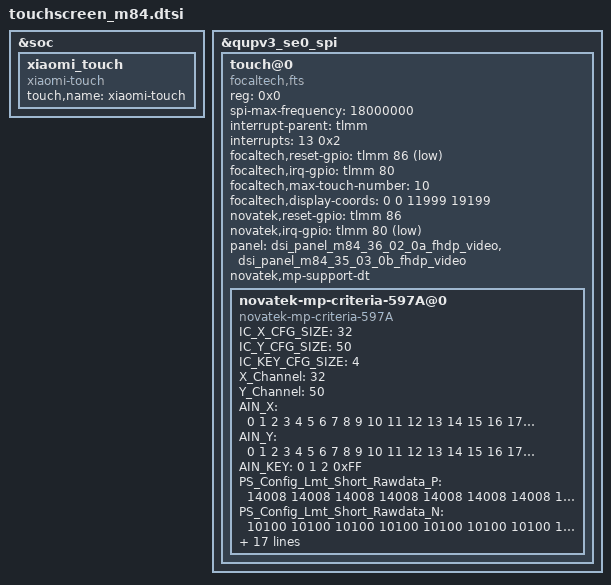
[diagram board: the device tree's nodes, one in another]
/*
 * TouchScreen Device Tree For Xiaomi m84
 */
&soc {
	xiaomi_touch {
		status = "okay";
		compatible = "xiaomi-touch";
		touch,name = "xiaomi-touch";
	};
};

&qupv3_se0_spi {
	status = "okay";
		touch@0 {
			compatible = "focaltech,fts","novatek,NVT-ts-spi";
			reg = <0x0>;
			status = "ok";
			spi-max-frequency = <18000000>;
			interrupt-parent = <&tlmm>;
			interrupts = <13 0x2>;
/***********************************focaltech dtsi **********************************/
			focaltech,reset-gpio = <&tlmm 86 0x01>;
			focaltech,irq-gpio = <&tlmm 80 0x02>;
			focaltech,max-touch-number = <10>;
			focaltech,display-coords =  <0 0 11999 19199>;

			/*pinctrl-names = "pmx_ts_active","pmx_ts_suspend","pmx_ts_release";
			pinctrl-0 = <&ts_int_active &ts_reset_active>;
			pinctrl-1 = <&ts_int_suspend &ts_reset_suspend>;
			pinctrl-2 = <&ts_release>; */
/***********************************novatek dtsi ************************************/ 
			novatek,reset-gpio = <&tlmm 86 0x00>;
			novatek,irq-gpio = <&tlmm 80 0x2001>;
			panel = <&dsi_panel_m84_36_02_0a_fhdp_video &dsi_panel_m84_35_03_0b_fhdp_video>;

			//novatek,pen-support;
			//novatek,stylus-resol-double;

			//novatek,spi-rd-fast-addr = <0x03F310>;

			/* MP */
			novatek,mp-support-dt;

		novatek-mp-criteria-597A@0 {
			#address-cells = <1>;
			#size-cells = <0>;
			compatible = "novatek-mp-criteria-597A";

			/* MP Config */
			IC_X_CFG_SIZE = <32>;
			IC_Y_CFG_SIZE = <50>;
			IC_KEY_CFG_SIZE = <4>;
			X_Channel = <32>;
			Y_Channel = <50>;
			AIN_X = <0 1 2 3 4 5 6 7 8 9 10 11 12 13 14 15 16 17 18 19 20 21 22 23 24 25 26 27 28 29 30 31>;
			AIN_Y = <0 1 2 3 4 5 6 7 8 9 10 11 12 13 14 15 16 17 18 19 20 21 22 23 24 25 26 27 28 29 30 31 32 33 34 35 36 37 38 39 40 41 42 43 44 45 46 47 48 49>;
			AIN_KEY = <0 1 2 0xFF>;

			/* MP Criteria */
			PS_Config_Lmt_Short_Rawdata_P = <
				14008 14008 14008 14008 14008 14008 14008 14008 14008 14008 14008 14008 14008 14008 14008 14008 14008 14008 14008 14008 14008 14008 14008 14008 14008 14008 14008 14008 14008 14008 14008 14008
				14008 14008 14008 14008 14008 14008 14008 14008 14008 14008 14008 14008 14008 14008 14008 14008 14008 14008 14008 14008 14008 14008 14008 14008 14008 14008 14008 14008 14008 14008 14008 14008
				14008 14008 14008 14008 14008 14008 14008 14008 14008 14008 14008 14008 14008 14008 14008 14008 14008 14008 14008 14008 14008 14008 14008 14008 14008 14008 14008 14008 14008 14008 14008 14008
				14008 14008 14008 14008 14008 14008 14008 14008 14008 14008 14008 14008 14008 14008 14008 14008 14008 14008 14008 14008 14008 14008 14008 14008 14008 14008 14008 14008 14008 14008 14008 14008
				14008 14008 14008 14008 14008 14008 14008 14008 14008 14008 14008 14008 14008 14008 14008 14008 14008 14008 14008 14008 14008 14008 14008 14008 14008 14008 14008 14008 14008 14008 14008 14008
				14008 14008 14008 14008 14008 14008 14008 14008 14008 14008 14008 14008 14008 14008 14008 14008 14008 14008 14008 14008 14008 14008 14008 14008 14008 14008 14008 14008 14008 14008 14008 14008
				14008 14008 14008 14008 14008 14008 14008 14008 14008 14008 14008 14008 14008 14008 14008 14008 14008 14008 14008 14008 14008 14008 14008 14008 14008 14008 14008 14008 14008 14008 14008 14008
				14008 14008 14008 14008 14008 14008 14008 14008 14008 14008 14008 14008 14008 14008 14008 14008 14008 14008 14008 14008 14008 14008 14008 14008 14008 14008 14008 14008 14008 14008 14008 14008
				14008 14008 14008 14008 14008 14008 14008 14008 14008 14008 14008 14008 14008 14008 14008 14008 14008 14008 14008 14008 14008 14008 14008 14008 14008 14008 14008 14008 14008 14008 14008 14008
				14008 14008 14008 14008 14008 14008 14008 14008 14008 14008 14008 14008 14008 14008 14008 14008 14008 14008 14008 14008 14008 14008 14008 14008 14008 14008 14008 14008 14008 14008 14008 14008
				14008 14008 14008 14008 14008 14008 14008 14008 14008 14008 14008 14008 14008 14008 14008 14008 14008 14008 14008 14008 14008 14008 14008 14008 14008 14008 14008 14008 14008 14008 14008 14008
				14008 14008 14008 14008 14008 14008 14008 14008 14008 14008 14008 14008 14008 14008 14008 14008 14008 14008 14008 14008 14008 14008 14008 14008 14008 14008 14008 14008 14008 14008 14008 14008
				14008 14008 14008 14008 14008 14008 14008 14008 14008 14008 14008 14008 14008 14008 14008 14008 14008 14008 14008 14008 14008 14008 14008 14008 14008 14008 14008 14008 14008 14008 14008 14008
				14008 14008 14008 14008 14008 14008 14008 14008 14008 14008 14008 14008 14008 14008 14008 14008 14008 14008 14008 14008 14008 14008 14008 14008 14008 14008 14008 14008 14008 14008 14008 14008
				14008 14008 14008 14008 14008 14008 14008 14008 14008 14008 14008 14008 14008 14008 14008 14008 14008 14008 14008 14008 14008 14008 14008 14008 14008 14008 14008 14008 14008 14008 14008 14008
				14008 14008 14008 14008 14008 14008 14008 14008 14008 14008 14008 14008 14008 14008 14008 14008 14008 14008 14008 14008 14008 14008 14008 14008 14008 14008 14008 14008 14008 14008 14008 14008
				14008 14008 14008 14008 14008 14008 14008 14008 14008 14008 14008 14008 14008 14008 14008 14008 14008 14008 14008 14008 14008 14008 14008 14008 14008 14008 14008 14008 14008 14008 14008 14008
				14008 14008 14008 14008 14008 14008 14008 14008 14008 14008 14008 14008 14008 14008 14008 14008 14008 14008 14008 14008 14008 14008 14008 14008 14008 14008 14008 14008 14008 14008 14008 14008
				14008 14008 14008 14008 14008 14008 14008 14008 14008 14008 14008 14008 14008 14008 14008 14008 14008 14008 14008 14008 14008 14008 14008 14008 14008 14008 14008 14008 14008 14008 14008 14008
				14008 14008 14008 14008 14008 14008 14008 14008 14008 14008 14008 14008 14008 14008 14008 14008 14008 14008 14008 14008 14008 14008 14008 14008 14008 14008 14008 14008 14008 14008 14008 14008
				14008 14008 14008 14008 14008 14008 14008 14008 14008 14008 14008 14008 14008 14008 14008 14008 14008 14008 14008 14008 14008 14008 14008 14008 14008 14008 14008 14008 14008 14008 14008 14008
				14008 14008 14008 14008 14008 14008 14008 14008 14008 14008 14008 14008 14008 14008 14008 14008 14008 14008 14008 14008 14008 14008 14008 14008 14008 14008 14008 14008 14008 14008 14008 14008
				14008 14008 14008 14008 14008 14008 14008 14008 14008 14008 14008 14008 14008 14008 14008 14008 14008 14008 14008 14008 14008 14008 14008 14008 14008 14008 14008 14008 14008 14008 14008 14008
				14008 14008 14008 14008 14008 14008 14008 14008 14008 14008 14008 14008 14008 14008 14008 14008 14008 14008 14008 14008 14008 14008 14008 14008 14008 14008 14008 14008 14008 14008 14008 14008
				14008 14008 14008 14008 14008 14008 14008 14008 14008 14008 14008 14008 14008 14008 14008 14008 14008 14008 14008 14008 14008 14008 14008 14008 14008 14008 14008 14008 14008 14008 14008 14008
				14008 14008 14008 14008 14008 14008 14008 14008 14008 14008 14008 14008 14008 14008 14008 14008 14008 14008 14008 14008 14008 14008 14008 14008 14008 14008 14008 14008 14008 14008 14008 14008
				14008 14008 14008 14008 14008 14008 14008 14008 14008 14008 14008 14008 14008 14008 14008 14008 14008 14008 14008 14008 14008 14008 14008 14008 14008 14008 14008 14008 14008 14008 14008 14008
				14008 14008 14008 14008 14008 14008 14008 14008 14008 14008 14008 14008 14008 14008 14008 14008 14008 14008 14008 14008 14008 14008 14008 14008 14008 14008 14008 14008 14008 14008 14008 14008
				14008 14008 14008 14008 14008 14008 14008 14008 14008 14008 14008 14008 14008 14008 14008 14008 14008 14008 14008 14008 14008 14008 14008 14008 14008 14008 14008 14008 14008 14008 14008 14008
				14008 14008 14008 14008 14008 14008 14008 14008 14008 14008 14008 14008 14008 14008 14008 14008 14008 14008 14008 14008 14008 14008 14008 14008 14008 14008 14008 14008 14008 14008 14008 14008
				14008 14008 14008 14008 14008 14008 14008 14008 14008 14008 14008 14008 14008 14008 14008 14008 14008 14008 14008 14008 14008 14008 14008 14008 14008 14008 14008 14008 14008 14008 14008 14008
				14008 14008 14008 14008 14008 14008 14008 14008 14008 14008 14008 14008 14008 14008 14008 14008 14008 14008 14008 14008 14008 14008 14008 14008 14008 14008 14008 14008 14008 14008 14008 14008
				14008 14008 14008 14008 14008 14008 14008 14008 14008 14008 14008 14008 14008 14008 14008 14008 14008 14008 14008 14008 14008 14008 14008 14008 14008 14008 14008 14008 14008 14008 14008 14008
				14008 14008 14008 14008 14008 14008 14008 14008 14008 14008 14008 14008 14008 14008 14008 14008 14008 14008 14008 14008 14008 14008 14008 14008 14008 14008 14008 14008 14008 14008 14008 14008
				14008 14008 14008 14008 14008 14008 14008 14008 14008 14008 14008 14008 14008 14008 14008 14008 14008 14008 14008 14008 14008 14008 14008 14008 14008 14008 14008 14008 14008 14008 14008 14008
				14008 14008 14008 14008 14008 14008 14008 14008 14008 14008 14008 14008 14008 14008 14008 14008 14008 14008 14008 14008 14008 14008 14008 14008 14008 14008 14008 14008 14008 14008 14008 14008
				14008 14008 14008 14008 14008 14008 14008 14008 14008 14008 14008 14008 14008 14008 14008 14008 14008 14008 14008 14008 14008 14008 14008 14008 14008 14008 14008 14008 14008 14008 14008 14008
				14008 14008 14008 14008 14008 14008 14008 14008 14008 14008 14008 14008 14008 14008 14008 14008 14008 14008 14008 14008 14008 14008 14008 14008 14008 14008 14008 14008 14008 14008 14008 14008
				14008 14008 14008 14008 14008 14008 14008 14008 14008 14008 14008 14008 14008 14008 14008 14008 14008 14008 14008 14008 14008 14008 14008 14008 14008 14008 14008 14008 14008 14008 14008 14008
				14008 14008 14008 14008 14008 14008 14008 14008 14008 14008 14008 14008 14008 14008 14008 14008 14008 14008 14008 14008 14008 14008 14008 14008 14008 14008 14008 14008 14008 14008 14008 14008
				14008 14008 14008 14008 14008 14008 14008 14008 14008 14008 14008 14008 14008 14008 14008 14008 14008 14008 14008 14008 14008 14008 14008 14008 14008 14008 14008 14008 14008 14008 14008 14008
				14008 14008 14008 14008 14008 14008 14008 14008 14008 14008 14008 14008 14008 14008 14008 14008 14008 14008 14008 14008 14008 14008 14008 14008 14008 14008 14008 14008 14008 14008 14008 14008
				14008 14008 14008 14008 14008 14008 14008 14008 14008 14008 14008 14008 14008 14008 14008 14008 14008 14008 14008 14008 14008 14008 14008 14008 14008 14008 14008 14008 14008 14008 14008 14008
				14008 14008 14008 14008 14008 14008 14008 14008 14008 14008 14008 14008 14008 14008 14008 14008 14008 14008 14008 14008 14008 14008 14008 14008 14008 14008 14008 14008 14008 14008 14008 14008
				14008 14008 14008 14008 14008 14008 14008 14008 14008 14008 14008 14008 14008 14008 14008 14008 14008 14008 14008 14008 14008 14008 14008 14008 14008 14008 14008 14008 14008 14008 14008 14008
				14008 14008 14008 14008 14008 14008 14008 14008 14008 14008 14008 14008 14008 14008 14008 14008 14008 14008 14008 14008 14008 14008 14008 14008 14008 14008 14008 14008 14008 14008 14008 14008
				14008 14008 14008 14008 14008 14008 14008 14008 14008 14008 14008 14008 14008 14008 14008 14008 14008 14008 14008 14008 14008 14008 14008 14008 14008 14008 14008 14008 14008 14008 14008 14008
				14008 14008 14008 14008 14008 14008 14008 14008 14008 14008 14008 14008 14008 14008 14008 14008 14008 14008 14008 14008 14008 14008 14008 14008 14008 14008 14008 14008 14008 14008 14008 14008
				14008 14008 14008 14008 14008 14008 14008 14008 14008 14008 14008 14008 14008 14008 14008 14008 14008 14008 14008 14008 14008 14008 14008 14008 14008 14008 14008 14008 14008 14008 14008 14008
				14008 14008 14008 14008 14008 14008 14008 14008 14008 14008 14008 14008 14008 14008 14008 14008 14008 14008 14008 14008 14008 14008 14008 14008 14008 14008 14008 14008 14008 14008 14008 14008
				14008 14008 14008>;

			PS_Config_Lmt_Short_Rawdata_N = <
				10100 10100 10100 10100 10100 10100 10100 10100 10100 10100 10100 10100 10100 10100 10100 10100 10100 10100 10100 10100 10100 10100 10100 10100 10100 10100 10100 10100 10100 10100 10100 10100
				10100 10100 10100 10100 10100 10100 10100 10100 10100 10100 10100 10100 10100 10100 10100 10100 10100 10100 10100 10100 10100 10100 10100 10100 10100 10100 10100 10100 10100 10100 10100 10100
				10100 10100 10100 10100 10100 10100 10100 10100 10100 10100 10100 10100 10100 10100 10100 10100 10100 10100 10100 10100 10100 10100 10100 10100 10100 10100 10100 10100 10100 10100 10100 10100
				10100 10100 10100 10100 10100 10100 10100 10100 10100 10100 10100 10100 10100 10100 10100 10100 10100 10100 10100 10100 10100 10100 10100 10100 10100 10100 10100 10100 10100 10100 10100 10100
				10100 10100 10100 10100 10100 10100 10100 10100 10100 10100 10100 10100 10100 10100 10100 10100 10100 10100 10100 10100 10100 10100 10100 10100 10100 10100 10100 10100 10100 10100 10100 10100
				10100 10100 10100 10100 10100 10100 10100 10100 10100 10100 10100 10100 10100 10100 10100 10100 10100 10100 10100 10100 10100 10100 10100 10100 10100 10100 10100 10100 10100 10100 10100 10100
				10100 10100 10100 10100 10100 10100 10100 10100 10100 10100 10100 10100 10100 10100 10100 10100 10100 10100 10100 10100 10100 10100 10100 10100 10100 10100 10100 10100 10100 10100 10100 10100
				10100 10100 10100 10100 10100 10100 10100 10100 10100 10100 10100 10100 10100 10100 10100 10100 10100 10100 10100 10100 10100 10100 10100 10100 10100 10100 10100 10100 10100 10100 10100 10100
				10100 10100 10100 10100 10100 10100 10100 10100 10100 10100 10100 10100 10100 10100 10100 10100 10100 10100 10100 10100 10100 10100 10100 10100 10100 10100 10100 10100 10100 10100 10100 10100
				10100 10100 10100 10100 10100 10100 10100 10100 10100 10100 10100 10100 10100 10100 10100 10100 10100 10100 10100 10100 10100 10100 10100 10100 10100 10100 10100 10100 10100 10100 10100 10100
				10100 10100 10100 10100 10100 10100 10100 10100 10100 10100 10100 10100 10100 10100 10100 10100 10100 10100 10100 10100 10100 10100 10100 10100 10100 10100 10100 10100 10100 10100 10100 10100
				10100 10100 10100 10100 10100 10100 10100 10100 10100 10100 10100 10100 10100 10100 10100 10100 10100 10100 10100 10100 10100 10100 10100 10100 10100 10100 10100 10100 10100 10100 10100 10100
				10100 10100 10100 10100 10100 10100 10100 10100 10100 10100 10100 10100 10100 10100 10100 10100 10100 10100 10100 10100 10100 10100 10100 10100 10100 10100 10100 10100 10100 10100 10100 10100
				10100 10100 10100 10100 10100 10100 10100 10100 10100 10100 10100 10100 10100 10100 10100 10100 10100 10100 10100 10100 10100 10100 10100 10100 10100 10100 10100 10100 10100 10100 10100 10100
				10100 10100 10100 10100 10100 10100 10100 10100 10100 10100 10100 10100 10100 10100 10100 10100 10100 10100 10100 10100 10100 10100 10100 10100 10100 10100 10100 10100 10100 10100 10100 10100
				10100 10100 10100 10100 10100 10100 10100 10100 10100 10100 10100 10100 10100 10100 10100 10100 10100 10100 10100 10100 10100 10100 10100 10100 10100 10100 10100 10100 10100 10100 10100 10100
				10100 10100 10100 10100 10100 10100 10100 10100 10100 10100 10100 10100 10100 10100 10100 10100 10100 10100 10100 10100 10100 10100 10100 10100 10100 10100 10100 10100 10100 10100 10100 10100
				10100 10100 10100 10100 10100 10100 10100 10100 10100 10100 10100 10100 10100 10100 10100 10100 10100 10100 10100 10100 10100 10100 10100 10100 10100 10100 10100 10100 10100 10100 10100 10100
				10100 10100 10100 10100 10100 10100 10100 10100 10100 10100 10100 10100 10100 10100 10100 10100 10100 10100 10100 10100 10100 10100 10100 10100 10100 10100 10100 10100 10100 10100 10100 10100
				10100 10100 10100 10100 10100 10100 10100 10100 10100 10100 10100 10100 10100 10100 10100 10100 10100 10100 10100 10100 10100 10100 10100 10100 10100 10100 10100 10100 10100 10100 10100 10100
				10100 10100 10100 10100 10100 10100 10100 10100 10100 10100 10100 10100 10100 10100 10100 10100 10100 10100 10100 10100 10100 10100 10100 10100 10100 10100 10100 10100 10100 10100 10100 10100
				10100 10100 10100 10100 10100 10100 10100 10100 10100 10100 10100 10100 10100 10100 10100 10100 10100 10100 10100 10100 10100 10100 10100 10100 10100 10100 10100 10100 10100 10100 10100 10100
				10100 10100 10100 10100 10100 10100 10100 10100 10100 10100 10100 10100 10100 10100 10100 10100 10100 10100 10100 10100 10100 10100 10100 10100 10100 10100 10100 10100 10100 10100 10100 10100
				10100 10100 10100 10100 10100 10100 10100 10100 10100 10100 10100 10100 10100 10100 10100 10100 10100 10100 10100 10100 10100 10100 10100 10100 10100 10100 10100 10100 10100 10100 10100 10100
				10100 10100 10100 10100 10100 10100 10100 10100 10100 10100 10100 10100 10100 10100 10100 10100 10100 10100 10100 10100 10100 10100 10100 10100 10100 10100 10100 10100 10100 10100 10100 10100
				10100 10100 10100 10100 10100 10100 10100 10100 10100 10100 10100 10100 10100 10100 10100 10100 10100 10100 10100 10100 10100 10100 10100 10100 10100 10100 10100 10100 10100 10100 10100 10100
				10100 10100 10100 10100 10100 10100 10100 10100 10100 10100 10100 10100 10100 10100 10100 10100 10100 10100 10100 10100 10100 10100 10100 10100 10100 10100 10100 10100 10100 10100 10100 10100
				10100 10100 10100 10100 10100 10100 10100 10100 10100 10100 10100 10100 10100 10100 10100 10100 10100 10100 10100 10100 10100 10100 10100 10100 10100 10100 10100 10100 10100 10100 10100 10100
				10100 10100 10100 10100 10100 10100 10100 10100 10100 10100 10100 10100 10100 10100 10100 10100 10100 10100 10100 10100 10100 10100 10100 10100 10100 10100 10100 10100 10100 10100 10100 10100
				10100 10100 10100 10100 10100 10100 10100 10100 10100 10100 10100 10100 10100 10100 10100 10100 10100 10100 10100 10100 10100 10100 10100 10100 10100 10100 10100 10100 10100 10100 10100 10100
				10100 10100 10100 10100 10100 10100 10100 10100 10100 10100 10100 10100 10100 10100 10100 10100 10100 10100 10100 10100 10100 10100 10100 10100 10100 10100 10100 10100 10100 10100 10100 10100
				10100 10100 10100 10100 10100 10100 10100 10100 10100 10100 10100 10100 10100 10100 10100 10100 10100 10100 10100 10100 10100 10100 10100 10100 10100 10100 10100 10100 10100 10100 10100 10100
				10100 10100 10100 10100 10100 10100 10100 10100 10100 10100 10100 10100 10100 10100 10100 10100 10100 10100 10100 10100 10100 10100 10100 10100 10100 10100 10100 10100 10100 10100 10100 10100
				10100 10100 10100 10100 10100 10100 10100 10100 10100 10100 10100 10100 10100 10100 10100 10100 10100 10100 10100 10100 10100 10100 10100 10100 10100 10100 10100 10100 10100 10100 10100 10100
				10100 10100 10100 10100 10100 10100 10100 10100 10100 10100 10100 10100 10100 10100 10100 10100 10100 10100 10100 10100 10100 10100 10100 10100 10100 10100 10100 10100 10100 10100 10100 10100
				10100 10100 10100 10100 10100 10100 10100 10100 10100 10100 10100 10100 10100 10100 10100 10100 10100 10100 10100 10100 10100 10100 10100 10100 10100 10100 10100 10100 10100 10100 10100 10100
				10100 10100 10100 10100 10100 10100 10100 10100 10100 10100 10100 10100 10100 10100 10100 10100 10100 10100 10100 10100 10100 10100 10100 10100 10100 10100 10100 10100 10100 10100 10100 10100
				10100 10100 10100 10100 10100 10100 10100 10100 10100 10100 10100 10100 10100 10100 10100 10100 10100 10100 10100 10100 10100 10100 10100 10100 10100 10100 10100 10100 10100 10100 10100 10100
				10100 10100 10100 10100 10100 10100 10100 10100 10100 10100 10100 10100 10100 10100 10100 10100 10100 10100 10100 10100 10100 10100 10100 10100 10100 10100 10100 10100 10100 10100 10100 10100
				10100 10100 10100 10100 10100 10100 10100 10100 10100 10100 10100 10100 10100 10100 10100 10100 10100 10100 10100 10100 10100 10100 10100 10100 10100 10100 10100 10100 10100 10100 10100 10100
				10100 10100 10100 10100 10100 10100 10100 10100 10100 10100 10100 10100 10100 10100 10100 10100 10100 10100 10100 10100 10100 10100 10100 10100 10100 10100 10100 10100 10100 10100 10100 10100
				10100 10100 10100 10100 10100 10100 10100 10100 10100 10100 10100 10100 10100 10100 10100 10100 10100 10100 10100 10100 10100 10100 10100 10100 10100 10100 10100 10100 10100 10100 10100 10100
				10100 10100 10100 10100 10100 10100 10100 10100 10100 10100 10100 10100 10100 10100 10100 10100 10100 10100 10100 10100 10100 10100 10100 10100 10100 10100 10100 10100 10100 10100 10100 10100
				10100 10100 10100 10100 10100 10100 10100 10100 10100 10100 10100 10100 10100 10100 10100 10100 10100 10100 10100 10100 10100 10100 10100 10100 10100 10100 10100 10100 10100 10100 10100 10100
				10100 10100 10100 10100 10100 10100 10100 10100 10100 10100 10100 10100 10100 10100 10100 10100 10100 10100 10100 10100 10100 10100 10100 10100 10100 10100 10100 10100 10100 10100 10100 10100
				10100 10100 10100 10100 10100 10100 10100 10100 10100 10100 10100 10100 10100 10100 10100 10100 10100 10100 10100 10100 10100 10100 10100 10100 10100 10100 10100 10100 10100 10100 10100 10100
				10100 10100 10100 10100 10100 10100 10100 10100 10100 10100 10100 10100 10100 10100 10100 10100 10100 10100 10100 10100 10100 10100 10100 10100 10100 10100 10100 10100 10100 10100 10100 10100
				10100 10100 10100 10100 10100 10100 10100 10100 10100 10100 10100 10100 10100 10100 10100 10100 10100 10100 10100 10100 10100 10100 10100 10100 10100 10100 10100 10100 10100 10100 10100 10100
				10100 10100 10100 10100 10100 10100 10100 10100 10100 10100 10100 10100 10100 10100 10100 10100 10100 10100 10100 10100 10100 10100 10100 10100 10100 10100 10100 10100 10100 10100 10100 10100
				10100 10100 10100 10100 10100 10100 10100 10100 10100 10100 10100 10100 10100 10100 10100 10100 10100 10100 10100 10100 10100 10100 10100 10100 10100 10100 10100 10100 10100 10100 10100 10100
				10000 10000 10000>;

			PS_Config_Lmt_Open_Rawdata_P = <
				2654	3168	3193	3204	3166	3159	3155	3154	3183	3158	3126	3117	3084	3053	3043	3035	3070	3077	3035	3066	3137	3166	3116	3173	3162	3207	3150	3203	3192	3235	3180	3273
				2654	3172	3197	3211	3164	3162	3152	3154	3168	3145	3113	3106	3080	3047	3035	3032	3067	3077	3035	3071	3133	3161	3110	3166	3155	3200	3140	3194	3190	3238	3180	3270
				2664	3168	3190	3208	3190	3161	3154	3148	3208	3162	3126	3103	3103	3057	3046	3031	3075	3046	3035	3057	3131	3122	3117	3157	3164	3159	3154	3189	3187	3187	3185	3262
				2660	3162	3182	3200	3175	3147	3140	3130	3176	3131	3094	3073	3080	3032	3021	3004	3054	3024	3017	3039	3108	3099	3096	3136	3137	3130	3133	3164	3173	3172	3175	3245
				2592	3102	3150	3150	3109	3081	3098	3080	3113	3073	3049	3026	2998	2959	2959	2938	2997	2954	2923	2937	3059	3054	3014	3052	3109	3105	3064	3094	3145	3147	3112	3178
				2647	3158	3207	3214	3166	3141	3158	3141	3162	3123	3099	3075	3066	3029	3033	3012	3077	3033	2998	3011	3130	3119	3080	3115	3161	3157	3110	3143	3203	3203	3165	3224
				2626	3154	3176	3162	3145	3130	3119	3087	3143	3108	3071	3038	3024	2994	2984	2958	3010	2993	2966	2990	3075	3084	3068	3105	3126	3141	3120	3140	3172	3178	3169	3210
				2620	3150	3166	3155	3127	3116	3102	3071	3115	3078	3043	3010	3001	2970	2961	2934	2991	2973	2948	2972	3056	3063	3046	3082	3101	3119	3098	3119	3158	3171	3158	3200
				2627	3165	3183	3140	3138	3137	3129	3071	3138	3119	3084	3024	3014	3003	2979	2935	2977	2970	2956	2941	3043	3063	3050	3060	3095	3122	3098	3099	3134	3154	3140	3133
				2623	3158	3178	3134	3127	3127	3113	3057	3112	3095	3057	2997	2997	2986	2968	2919	2958	2949	2937	2926	3021	3042	3029	3042	3074	3101	3081	3082	3133	3154	3136	3126
				2647	3185	3169	3152	3145	3158	3116	3082	3150	3137	3074	3031	3032	3017	2983	2940	2982	2961	2962	2986	3053	3059	3061	3105	3108	3117	3110	3144	3152	3157	3161	3155
				2641	3179	3164	3147	3131	3143	3105	3064	3126	3108	3046	3001	3008	2991	2961	2919	2962	2942	2945	2969	3031	3039	3040	3088	3088	3094	3091	3131	3145	3147	3151	3144
				2678	3162	3158	3155	3147	3137	3096	3077	3145	3109	3047	3022	3022	2996	2961	2930	2989	2966	2980	2956	3063	3059	3075	3077	3115	3116	3126	3116	3164	3165	3185	3098
				2672	3161	3155	3150	3136	3123	3084	3063	3122	3082	3022	2996	2997	2972	2937	2909	2972	2949	2965	2942	3040	3040	3057	3060	3094	3098	3108	3103	3154	3155	3175	3087
				2700	3189	3185	3180	3138	3151	3123	3108	3134	3122	3078	3054	3008	3005	2987	2965	2980	2969	3003	2970	3050	3064	3105	3088	3102	3129	3147	3124	3157	3179	3194	3080
				2692	3186	3180	3176	3126	3140	3112	3095	3110	3098	3053	3029	2980	2976	2956	2935	2962	2955	2986	2954	3029	3047	3084	3071	3085	3110	3130	3116	3138	3158	3179	3061
				2724	3176	3171	3171	3134	3140	3103	3092	3129	3105	3053	3033	3000	2989	2962	2945	2986	2979	2938	2980	3061	3074	3042	3105	3115	3130	3085	3145	3169	3179	3143	3073
				2720	3173	3166	3165	3126	3129	3091	3077	3105	3081	3032	3011	2980	2966	2940	2921	2968	2961	2923	2963	3038	3054	3024	3087	3096	3112	3077	3134	3159	3172	3133	3060
				2755	3178	3196	3172	3141	3143	3129	3096	3133	3108	3077	3036	3001	2997	2983	2954	2975	3008	2983	2973	3053	3112	3089	3102	3113	3172	3136	3147	3173	3224	3203	3047
				2753	3173	3194	3165	3131	3129	3117	3082	3113	3085	3056	3012	2980	2975	2962	2931	2956	2994	2969	2959	3032	3094	3071	3085	3098	3158	3122	3133	3165	3214	3193	3035
				2805	3214	3207	3171	3154	3171	3131	3084	3141	3129	3075	3022	3008	3019	2983	2938	2962	2984	2984	2984	3045	3085	3096	3113	3105	3147	3148	3155	3157	3206	3214	3028
				2802	3213	3206	3169	3143	3161	3120	3073	3120	3110	3054	3004	2989	2997	2965	2919	2948	2969	2972	2975	3024	3068	3078	3094	3091	3133	3136	3147	3148	3199	3207	3021
				2829	3197	3207	3179	3159	3159	3133	3094	3154	3122	3080	3026	3021	3014	2983	2941	2956	2965	2965	2986	3040	3066	3077	3122	3096	3126	3127	3168	3157	3180	3186	3003
				2825	3197	3203	3176	3151	3151	3120	3080	3136	3102	3060	3007	3005	2993	2962	2920	2942	2949	2952	2975	3022	3046	3060	3106	3082	3113	3112	3157	3148	3173	3176	2990
				2849	3194	3213	3201	3140	3150	3141	3117	3124	3105	3081	3047	2993	2997	2989	2966	2944	2959	3008	2984	3035	3061	3126	3123	3091	3122	3176	3165	3155	3189	3242	2979
				2849	3197	3215	3200	3133	3138	3130	3105	3112	3089	3067	3032	2972	2979	2969	2948	2930	2947	2996	2973	3014	3045	3109	3108	3082	3113	3165	3159	3150	3183	3236	2969
				2921	3192	3215	3185	3189	3144	3138	3101	3166	3103	3082	3031	3024	2990	2977	2948	2948	2972	3010	2969	3045	3080	3133	3101	3110	3145	3180	3150	3172	3210	3249	2934
				2923	3190	3217	3183	3178	3134	3130	3091	3148	3084	3060	3012	3004	2972	2956	2927	2933	2958	2993	2955	3025	3063	3115	3084	3094	3131	3171	3136	3164	3199	3243	2924
				2954	3189	3210	3221	3192	3141	3129	3133	3171	3091	3059	3061	3033	2973	2961	2976	2968	2987	2969	2966	3070	3096	3098	3102	3136	3159	3148	3148	3201	3222	3221	2903
				2956	3192	3210	3222	3183	3134	3117	3120	3154	3074	3043	3046	3018	2958	2942	2961	2958	2976	2959	2956	3053	3081	3084	3087	3122	3147	3138	3138	3194	3217	3214	2900
				2948	3190	3222	3182	3154	3141	3140	3096	3136	3092	3077	3025	2998	2973	2975	2945	2954	2954	2986	2993	3057	3067	3113	3124	3119	3130	3169	3169	3185	3197	3241	2896
				2947	3190	3221	3183	3145	3134	3131	3087	3116	3071	3057	3005	2980	2958	2956	2928	2940	2947	2976	2983	3039	3052	3098	3110	3098	3116	3151	3157	3175	3190	3236	2889
				2965	3189	3164	3196	3133	3136	3081	3099	3112	3080	3015	3019	2972	2959	2907	2937	2917	2945	2973	2969	3028	3054	3106	3108	3091	3119	3161	3157	3162	3182	3236	2858
				2970	3193	3165	3193	3129	3127	3073	3089	3098	3066	2998	3004	2955	2942	2892	2920	2907	2934	2965	2959	3011	3040	3094	3095	3084	3109	3154	3150	3157	3180	3232	2851
				3049	3199	3221	3203	3190	3141	3136	3109	3161	3087	3064	3036	3011	2962	2951	2947	2949	2994	2940	2956	3061	3108	3075	3099	3137	3178	3133	3147	3210	3252	3213	2816
				3053	3200	3222	3200	3185	3136	3127	3099	3144	3074	3050	3021	3001	2954	2938	2938	2940	2982	2930	2951	3047	3094	3064	3087	3131	3171	3126	3141	3211	3250	3211	2816
				3063	3171	3229	3201	3172	3110	3137	3102	3133	3052	3070	3024	2984	2930	2963	2944	2973	2962	2968	2959	3089	3075	3098	3105	3161	3144	3148	3152	3234	3218	3222	2802
				3064	3176	3231	3203	3162	3103	3130	3095	3120	3038	3057	3010	2969	2916	2948	2927	2962	2951	2956	2952	3074	3064	3084	3094	3151	3137	3143	3152	3229	3217	3221	2800
				3130	3200	3190	3175	3197	3136	3098	3071	3159	3077	3024	2990	3010	2954	2912	2909	2900	2923	2970	2945	3015	3039	3105	3087	3091	3116	3157	3141	3164	3200	3229	2758
				3133	3204	3192	3173	3192	3131	3088	3066	3147	3063	3010	2976	2994	2940	2895	2895	2891	2912	2962	2935	3004	3026	3094	3077	3082	3110	3150	3137	3157	3197	3228	2752
				3102	3204	3224	3173	3138	3133	3126	3070	3106	3068	3053	2987	2956	2945	2935	2912	2896	2923	2926	2947	3015	3040	3063	3087	3091	3110	3122	3141	3166	3185	3211	2751
				3106	3206	3229	3175	3137	3127	3122	3063	3094	3060	3042	2976	2942	2927	2913	2893	2886	2914	2916	2937	3000	3025	3054	3077	3084	3105	3122	3140	3159	3176	3206	2744
				3141	3204	3217	3186	3147	3137	3119	3085	3109	3071	3043	3004	2962	2951	2931	2930	2909	2914	2942	2905	3026	3033	3085	3046	3112	3106	3150	3098	3199	3183	3245	2710
				3145	3208	3221	3187	3143	3130	3112	3078	3098	3060	3031	2991	2948	2937	2916	2916	2898	2905	2931	2893	3012	3018	3075	3036	3105	3098	3145	3096	3193	3179	3243	2703
				3277	3266	3304	3246	3266	3203	3207	3145	3232	3145	3133	3070	3085	3031	3024	3000	3019	3031	3053	3026	3138	3143	3200	3164	3215	3211	3260	3213	3292	3285	3339	2812
				3204	3190	3222	3162	3172	3108	3108	3046	3122	3035	3022	2958	2966	2913	2903	2884	2903	2917	2942	2917	3021	3033	3089	3060	3115	3116	3166	3127	3210	3203	3257	2728
				3246	3281	3274	3221	3222	3218	3180	3124	3187	3157	3115	3049	3046	3046	3005	2984	2991	2991	3025	3005	3108	3109	3161	3138	3185	3178	3214	3182	3266	3253	3297	2784
				3248	3288	3278	3227	3221	3214	3175	3119	3178	3150	3105	3040	3031	3032	2991	2968	2980	2982	3019	3001	3094	3096	3152	3129	3176	3173	3211	3180	3262	3250	3295	2780
				3232	3270	3269	3248	3218	3203	3172	3143	3185	3137	3099	3059	3043	3024	2990	2998	2969	3014	3001	3012	3084	3129	3141	3155	3158	3200	3197	3210	3236	3280	3281	2811
				3238	3273	3273	3246	3214	3194	3165	3134	3172	3126	3087	3049	3025	3005	2968	2976	2951	2998	2990	3000	3068	3115	3130	3145	3155	3196	3199	3208	3236	3277	3280	2807
				5120 5120 5120>;

			PS_Config_Lmt_Open_Rawdata_N = <
				1137	1357	1368	1373	1357	1354	1352	1351	1364	1353	1339	1336	1321	1308	1304	1300	1315	1318	1300	1314	1344	1357	1335	1360	1355	1374	1350	1372	1368	1386	1363	1402
				1137	1359	1370	1376	1356	1355	1351	1351	1357	1348	1334	1331	1320	1306	1300	1299	1314	1318	1300	1316	1342	1354	1333	1357	1352	1371	1345	1369	1367	1387	1363	1401
				1141	1357	1367	1375	1367	1354	1351	1349	1375	1355	1339	1330	1330	1310	1305	1299	1318	1305	1300	1310	1342	1338	1336	1353	1356	1354	1351	1366	1366	1366	1365	1398
				1140	1355	1363	1371	1360	1348	1345	1341	1361	1342	1326	1317	1320	1299	1294	1287	1309	1296	1293	1302	1332	1328	1327	1344	1344	1341	1342	1356	1360	1359	1360	1390
				1111	1329	1350	1350	1332	1320	1327	1320	1334	1317	1306	1297	1285	1268	1268	1259	1284	1266	1252	1258	1311	1309	1291	1308	1332	1330	1313	1326	1348	1348	1333	1362
				1134	1353	1374	1377	1357	1346	1353	1346	1355	1338	1328	1318	1314	1298	1300	1291	1318	1300	1285	1290	1341	1336	1320	1335	1354	1353	1333	1347	1372	1372	1356	1381
				1125	1351	1361	1355	1348	1341	1336	1323	1347	1332	1316	1302	1296	1283	1279	1267	1290	1282	1271	1281	1318	1321	1315	1330	1339	1346	1337	1345	1359	1362	1358	1375
				1123	1350	1357	1352	1340	1335	1329	1316	1335	1319	1304	1290	1286	1273	1269	1257	1282	1274	1263	1273	1309	1312	1305	1321	1329	1336	1327	1336	1353	1359	1353	1371
				1126	1356	1364	1345	1345	1344	1341	1316	1345	1336	1321	1296	1291	1287	1276	1258	1276	1273	1267	1260	1304	1312	1307	1311	1326	1338	1327	1328	1343	1351	1345	1342
				1124	1353	1362	1343	1340	1340	1334	1310	1333	1326	1310	1284	1284	1279	1272	1251	1267	1264	1258	1254	1294	1303	1298	1303	1317	1329	1320	1321	1342	1351	1344	1339
				1134	1365	1358	1351	1348	1353	1335	1321	1350	1344	1317	1299	1299	1293	1278	1260	1278	1269	1269	1279	1308	1311	1312	1330	1332	1336	1333	1347	1351	1353	1354	1352
				1132	1362	1356	1348	1342	1347	1330	1313	1339	1332	1305	1286	1289	1282	1269	1251	1269	1261	1262	1272	1299	1302	1303	1323	1323	1326	1324	1342	1348	1348	1350	1347
				1147	1355	1353	1352	1348	1344	1327	1318	1348	1332	1306	1295	1295	1284	1269	1255	1281	1271	1277	1267	1312	1311	1318	1318	1335	1335	1339	1335	1356	1356	1365	1327
				1145	1354	1352	1350	1344	1338	1321	1312	1338	1321	1295	1284	1284	1273	1258	1246	1273	1264	1270	1261	1303	1303	1310	1311	1326	1327	1332	1330	1351	1352	1360	1323
				1157	1366	1365	1363	1345	1350	1338	1332	1343	1338	1319	1309	1289	1288	1280	1270	1277	1272	1287	1273	1307	1313	1330	1323	1329	1341	1348	1339	1353	1362	1369	1320
				1153	1365	1363	1361	1339	1345	1333	1326	1333	1327	1308	1298	1277	1275	1267	1258	1269	1266	1279	1266	1298	1306	1321	1316	1322	1333	1341	1335	1345	1353	1362	1312
				1167	1361	1359	1359	1343	1345	1330	1325	1341	1330	1308	1300	1285	1281	1269	1262	1279	1276	1259	1277	1312	1317	1303	1330	1335	1341	1322	1348	1358	1362	1347	1317
				1165	1360	1357	1356	1339	1341	1324	1318	1330	1320	1299	1290	1277	1271	1260	1252	1272	1269	1252	1270	1302	1309	1296	1323	1327	1333	1318	1343	1354	1359	1342	1311
				1180	1362	1369	1359	1346	1347	1341	1327	1342	1332	1318	1301	1286	1284	1278	1266	1275	1289	1278	1274	1308	1333	1324	1329	1334	1359	1344	1348	1360	1381	1372	1306
				1180	1360	1369	1356	1342	1341	1336	1321	1334	1322	1309	1291	1277	1275	1269	1256	1267	1283	1272	1268	1299	1326	1316	1322	1327	1353	1338	1342	1356	1377	1368	1300
				1202	1377	1374	1359	1351	1359	1342	1321	1346	1341	1318	1295	1289	1294	1278	1259	1269	1279	1279	1279	1305	1322	1327	1334	1330	1348	1349	1352	1353	1374	1377	1297
				1201	1377	1374	1358	1347	1354	1337	1317	1337	1333	1309	1287	1281	1284	1270	1251	1263	1272	1273	1275	1296	1315	1319	1326	1324	1342	1344	1348	1349	1371	1374	1294
				1212	1370	1374	1362	1354	1354	1342	1326	1351	1338	1320	1297	1294	1291	1278	1260	1267	1270	1270	1279	1303	1314	1318	1338	1327	1339	1340	1357	1353	1363	1365	1287
				1210	1370	1372	1361	1350	1350	1337	1320	1344	1329	1311	1288	1288	1282	1269	1251	1261	1264	1265	1275	1295	1305	1311	1331	1321	1334	1333	1353	1349	1360	1361	1281
				1221	1369	1377	1372	1345	1350	1346	1336	1339	1330	1320	1306	1282	1284	1281	1271	1261	1268	1289	1279	1300	1312	1339	1338	1324	1338	1361	1356	1352	1366	1389	1276
				1221	1370	1378	1371	1342	1345	1341	1330	1333	1324	1314	1299	1273	1276	1272	1263	1255	1263	1284	1274	1291	1305	1332	1332	1321	1334	1356	1354	1350	1364	1387	1272
				1252	1368	1378	1365	1366	1347	1345	1329	1357	1330	1321	1299	1296	1281	1276	1263	1263	1273	1290	1272	1305	1320	1342	1329	1333	1348	1363	1350	1359	1375	1392	1257
				1252	1367	1378	1364	1362	1343	1341	1324	1349	1321	1311	1291	1287	1273	1267	1254	1257	1267	1282	1266	1296	1312	1335	1321	1326	1342	1359	1344	1356	1371	1390	1253
				1266	1366	1375	1380	1368	1346	1341	1342	1359	1324	1311	1312	1300	1274	1269	1275	1272	1280	1272	1271	1315	1327	1327	1329	1344	1354	1349	1349	1372	1381	1380	1244
				1267	1368	1375	1381	1364	1343	1336	1337	1351	1317	1304	1305	1293	1267	1261	1269	1267	1275	1268	1267	1308	1320	1321	1323	1338	1348	1345	1345	1369	1378	1377	1243
				1263	1367	1381	1363	1351	1346	1345	1327	1344	1325	1318	1296	1285	1274	1275	1262	1266	1266	1279	1282	1310	1314	1334	1339	1336	1341	1358	1358	1365	1370	1389	1241
				1263	1367	1380	1364	1348	1343	1342	1323	1335	1316	1310	1288	1277	1267	1267	1255	1260	1263	1275	1278	1302	1308	1327	1333	1327	1335	1350	1353	1360	1367	1387	1238
				1270	1366	1356	1369	1342	1344	1320	1328	1333	1320	1292	1294	1273	1268	1246	1258	1250	1262	1274	1272	1297	1309	1331	1332	1324	1336	1354	1353	1355	1363	1387	1225
				1273	1368	1356	1368	1341	1340	1317	1324	1327	1314	1285	1287	1266	1261	1239	1251	1246	1257	1270	1268	1290	1303	1326	1326	1321	1332	1351	1350	1353	1363	1385	1222
				1306	1371	1380	1372	1367	1346	1344	1332	1354	1323	1313	1301	1290	1269	1264	1263	1264	1283	1260	1267	1312	1332	1318	1328	1344	1362	1342	1348	1375	1393	1377	1207
				1308	1371	1381	1371	1365	1344	1340	1328	1347	1317	1307	1294	1286	1266	1259	1259	1260	1278	1255	1264	1306	1326	1313	1323	1342	1359	1339	1346	1376	1393	1376	1207
				1312	1359	1384	1372	1359	1333	1344	1329	1342	1308	1315	1296	1279	1255	1270	1261	1274	1269	1272	1268	1324	1318	1327	1330	1354	1347	1349	1351	1386	1379	1381	1201
				1313	1361	1384	1372	1355	1330	1341	1326	1337	1302	1310	1290	1272	1249	1263	1254	1269	1264	1267	1265	1317	1313	1321	1326	1350	1344	1347	1351	1384	1378	1380	1200
				1341	1371	1367	1360	1370	1344	1327	1316	1354	1318	1296	1281	1290	1266	1248	1246	1243	1252	1273	1262	1292	1302	1330	1323	1324	1335	1353	1346	1356	1371	1384	1182
				1342	1373	1368	1360	1368	1342	1323	1314	1348	1312	1290	1275	1283	1260	1240	1240	1239	1248	1269	1258	1287	1297	1326	1318	1321	1333	1350	1344	1353	1370	1383	1179
				1329	1373	1381	1360	1345	1342	1339	1315	1331	1315	1308	1280	1267	1262	1258	1248	1241	1252	1254	1263	1292	1303	1312	1323	1324	1333	1338	1346	1357	1365	1376	1179
				1331	1374	1384	1360	1344	1340	1338	1312	1326	1311	1303	1275	1261	1254	1248	1240	1237	1249	1249	1258	1285	1296	1309	1318	1321	1330	1338	1345	1354	1361	1374	1176
				1346	1373	1378	1365	1348	1344	1336	1322	1332	1316	1304	1287	1269	1264	1256	1255	1246	1249	1261	1245	1297	1300	1322	1305	1333	1331	1350	1327	1371	1364	1390	1161
				1348	1375	1380	1366	1347	1341	1333	1319	1327	1311	1299	1282	1263	1258	1249	1249	1242	1245	1256	1240	1291	1293	1318	1301	1330	1327	1348	1327	1368	1362	1390	1158
				1404	1399	1416	1391	1399	1372	1374	1348	1385	1348	1342	1315	1322	1299	1296	1285	1294	1299	1308	1297	1345	1347	1371	1356	1378	1376	1397	1377	1411	1408	1431	1205
				1373	1367	1381	1355	1359	1332	1332	1305	1338	1300	1295	1267	1271	1248	1244	1236	1244	1250	1261	1250	1294	1300	1324	1311	1335	1335	1357	1340	1375	1372	1396	1169
				1391	1406	1403	1380	1381	1379	1363	1339	1366	1353	1335	1306	1305	1305	1288	1279	1282	1282	1296	1288	1332	1332	1354	1345	1365	1362	1377	1363	1399	1394	1413	1193
				1392	1409	1405	1383	1380	1377	1360	1336	1362	1350	1330	1303	1299	1299	1282	1272	1277	1278	1294	1286	1326	1327	1351	1341	1361	1360	1376	1363	1398	1393	1412	1191
				1385	1401	1401	1392	1379	1372	1359	1347	1365	1344	1328	1311	1304	1296	1281	1285	1272	1291	1286	1291	1321	1341	1346	1352	1353	1371	1370	1375	1387	1405	1406	1204
				1387	1402	1402	1391	1377	1369	1356	1343	1359	1339	1323	1306	1296	1288	1272	1275	1264	1285	1281	1285	1315	1335	1341	1348	1352	1369	1371	1375	1387	1404	1405	1203
				(-511) (-511) (-511)>;

			PS_Config_Lmt_FW_Rawdata_P = <
				2198	2254	2245	2230	2223	2234	2214	2238	2237	2231	2231	2235	2220	2247	2217	2210	2247	2231	2245	2210	2258	2241	2233	2244	2219	2242	2213	2227	2241	2230	2223	2216
				2262	2266	2240	2242	2252	2245	2242	2268	2248	2206	2234	2242	2240	2263	2258	2270	2191	2273	2289	2237	2226	2238	2227	2238	2219	2242	2297	2251	2196	2234	2171	2224
				2234	2214	2219	2261	2251	2245	2234	2182	2262	2226	2209	2223	2224	2228	2203	2202	2252	2258	2276	2202	2268	2254	2245	2217	2184	2223	2228	2242	2177	2277	2270	2210
				2234	2241	2242	2205	2241	2228	2214	2221	2198	2249	2252	2188	2207	2223	2193	2220	2251	2256	2268	2192	2248	2224	2186	2237	2247	2247	2248	2258	2200	2259	2202	2242
				2245	2198	2252	2212	2214	2272	2249	2219	2221	2221	2249	2256	2184	2174	2245	2251	2230	2221	2227	2231	2233	2212	2230	2195	2223	2220	2262	2209	2191	2245	2226	2212
				2251	2242	2220	2221	2241	2262	2255	2254	2206	2214	2224	2230	2269	2266	2240	2220	2234	2221	2247	2210	2237	2261	2228	2255	2235	2205	2258	2209	2245	2213	2203	2224
				2228	2198	2242	2223	2209	2245	2234	2275	2261	2258	2262	2207	2234	2268	2266	2256	2210	2248	2235	2214	2216	2251	2268	2212	2237	2214	2235	2220	2233	2245	2234	2279
				2234	2270	2205	2223	2223	2231	2223	2234	2223	2209	2206	2294	2228	2241	2252	2241	2209	2252	2219	2221	2220	2251	2205	2237	2213	2224	2237	2234	2212	2227	2214	2228
				2205	2242	2226	2212	2242	2279	2261	2223	2266	2241	2221	2248	2268	2233	2230	2209	2275	2235	2206	2223	2265	2220	2230	2248	2240	2270	2226	2251	2230	2196	2217	2241
				2249	2192	2255	2216	2224	2238	2251	2238	2279	2245	2233	2220	2237	2221	2251	2214	2277	2248	2210	2199	2263	2261	2259	2228	2258	2233	2231	2241	2209	2237	2221	2203
				2235	2210	2255	2240	2202	2209	2241	2219	2214	2226	2231	2261	2206	2220	2262	2255	2228	2261	2223	2219	2227	2213	2238	2254	2231	2223	2251	2254	2249	2193	2245	2241
				2235	2240	2219	2212	2221	2220	2252	2272	2240	2272	2234	2234	2226	2206	2277	2249	2217	2242	2207	2252	2206	2228	2231	2237	2216	2196	2238	2223	2230	2272	2220	2227
				2233	2244	2227	2254	2263	2227	2254	2231	2242	2224	2196	2256	2241	2251	2196	2207	2210	2224	2245	2249	2221	2216	2235	2265	2242	2263	2212	2198	2212	2238	2226	2220
				2220	2241	2227	2226	2254	2237	2256	2244	2252	2230	2277	2200	2248	2244	2186	2205	2203	2226	2227	2268	2200	2262	2244	2220	2241	2181	2233	2195	2226	2230	2227	2241
				2242	2235	2263	2272	2231	2219	2235	2233	2258	2241	2193	2226	2252	2235	2206	2227	2235	2249	2237	2238	2235	2252	2240	2242	2209	2221	2234	2251	2254	2247	2221	2213
				2256	2226	2216	2248	2207	2223	2219	2254	2202	2247	2262	2242	2242	2242	2192	2224	2223	2235	2220	2245	2217	2226	2212	2259	2249	2247	2256	2223	2219	2261	2248	2242
				2254	2221	2210	2216	2244	2265	2237	2244	2270	2251	2241	2256	2263	2249	2212	2224	2227	2286	2231	2192	2210	2262	2242	2272	2240	2234	2227	2249	2251	2247	2242	2256
				2203	2255	2256	2258	2244	2268	2237	2265	2189	2226	2249	2217	2247	2255	2231	2219	2228	2279	2213	2234	2254	2237	2228	2220	2223	2252	2234	2241	2241	2182	2207	2248
				2255	2242	2188	2249	2233	2248	2270	2213	2251	2247	2240	2240	2251	2227	2230	2196	2231	2217	2235	2254	2223	2213	2221	2210	2273	2276	2237	2255	2209	2233	2237	2227
				2210	2241	2296	2196	2209	2247	2235	2247	2237	2219	2228	2195	2237	2223	2240	2210	2233	2242	2240	2223	2238	2263	2248	2224	2219	2227	2219	2230	2237	2254	2217	2247
				2255	2251	2238	2255	2266	2235	2238	2221	2259	2231	2227	2242	2270	2217	2276	2214	2248	2265	2219	2249	2245	2249	2249	2231	2252	2203	2247	2248	2255	2242	2254	2234
				2220	2230	2275	2231	2256	2247	2237	2234	2224	2237	2241	2198	2258	2238	2247	2203	2221	2254	2238	2237	2252	2189	2227	2290	2220	2223	2231	2272	2244	2223	2231	2228
				2214	2238	2191	2241	2219	2207	2263	2230	2226	2227	2223	2237	2240	2245	2280	2231	2244	2262	2238	2221	2269	2263	2224	2231	2221	2234	2214	2261	2261	2213	2244	2217
				2255	2224	2284	2214	2262	2226	2275	2252	2223	2248	2238	2219	2237	2226	2249	2227	2216	2279	2227	2228	2210	2233	2242	2254	2247	2255	2216	2245	2227	2233	2219	2234
				2263	2238	2228	2212	2251	2235	2234	2198	2224	2226	2224	2207	2224	2268	2231	2263	2210	2213	2259	2255	2244	2214	2240	2235	2235	2205	2268	2214	2202	2245	2210	2216
				2233	2227	2249	2259	2268	2234	2210	2193	2240	2220	2238	2244	2224	2219	2224	2262	2178	2235	2221	2247	2214	2258	2202	2200	2234	2214	2259	2238	2203	2231	2276	2235
				2237	2282	2266	2227	2241	2212	2234	2195	2240	2255	2242	2196	2219	2238	2202	2209	2244	2238	2193	2231	2263	2247	2209	2249	2277	2223	2262	2233	2258	2233	2237	2214
				2234	2213	2220	2193	2261	2203	2249	2223	2247	2210	2209	2284	2241	2230	2212	2251	2238	2227	2275	2209	2226	2221	2234	2220	2258	2227	2270	2230	2245	2234	2247	2254
				2213	2227	2241	2234	2214	2247	2261	2237	2224	2233	2262	2219	2233	2205	2248	2235	2213	2248	2216	2217	2224	2272	2241	2220	2216	2230	2251	2268	2248	2262	2233	2228
				2230	2248	2212	2210	2224	2242	2273	2228	2231	2266	2213	2254	2227	2256	2210	2249	2265	2223	2220	2179	2247	2206	2242	2262	2248	2237	2266	2252	2234	2188	2226	2238
				2216	2240	2198	2205	2219	2248	2272	2252	2217	2217	2234	2256	2192	2182	2237	2237	2263	2259	2240	2209	2249	2268	2248	2207	2269	2256	2258	2238	2221	2223	2202	2198
				2220	2244	2279	2251	2206	2233	2280	2254	2245	2272	2238	2224	2269	2261	2224	2219	2237	2255	2223	2259	2248	2233	2228	2244	2256	2262	2248	2200	2276	2217	2289	2280
				2226	2273	2227	2254	2209	2244	2228	2251	2186	2223	2226	2228	2217	2205	2199	2238	2221	2231	2240	2256	2259	2261	2234	2252	2249	2235	2237	2220	2261	2241	2216	2245
				2237	2199	2249	2238	2210	2220	2224	2237	2231	2269	2263	2226	2263	2280	2251	2235	2217	2231	2209	2228	2207	2233	2265	2213	2259	2234	2227	2217	2244	2240	2214	2249
				2212	2242	2221	2221	2252	2227	2227	2258	2224	2234	2185	2249	2217	2221	2255	2242	2259	2223	2235	2216	2206	2259	2254	2234	2240	2237	2240	2230	2235	2212	2219	2240
				2207	2224	2263	2283	2245	2213	2244	2212	2234	2226	2240	2216	2251	2220	2227	2188	2248	2206	2212	2206	2256	2238	2233	2255	2230	2219	2216	2230	2214	2248	2261	2255
				2265	2231	2213	2254	2200	2247	2206	2261	2252	2193	2237	2248	2248	2214	2216	2262	2199	2221	2240	2210	2241	2230	2196	2205	2220	2227	2242	2216	2247	2247	2252	2256
				2234	2231	2276	2203	2261	2238	2221	2255	2248	2228	2234	2221	2206	2249	2235	2212	2275	2248	2262	2252	2248	2220	2221	2230	2226	2244	2216	2263	2237	2228	2252	2210
				2233	2217	2233	2237	2216	2237	2203	2207	2220	2248	2192	2216	2259	2207	2276	2241	2192	2247	2244	2214	2242	2245	2247	2217	2237	2230	2266	2240	2213	2238	2214	2248
				2248	2262	2205	2224	2203	2249	2234	2228	2191	2247	2228	2235	2230	2254	2212	2230	2273	2231	2241	2251	2242	2223	2242	2240	2233	2230	2227	2240	2245	2247	2245	2235
				2237	2223	2254	2242	2261	2238	2261	2255	2272	2247	2270	2240	2255	2259	2202	2242	2216	2230	2227	2206	2247	2245	2228	2212	2245	2214	2221	2263	2244	2252	2214	2230
				2233	2266	2240	2240	2242	2234	2237	2247	2269	2231	2209	2212	2210	2213	2217	2242	2244	2228	2233	2251	2216	2248	2235	2223	2254	2185	2251	2214	2241	2209	2251	2245
				2279	2237	2248	2198	2244	2214	2249	2207	2272	2259	2233	2205	2258	2242	2202	2226	2252	2251	2277	2210	2251	2252	2265	2213	2248	2238	2217	2228	2233	2237	2220	2200
				2234	2235	2228	2277	2227	2254	2221	2217	2272	2255	2240	2240	2214	2240	2254	2241	2210	2220	2205	2240	2205	2265	2270	2205	2266	2219	2254	2235	2258	2226	2240	2261
				2207	2212	2227	2251	2247	2221	2240	2199	2233	2205	2228	2224	2216	2231	2233	2195	2179	2258	2212	2233	2231	2280	2210	2235	2214	2248	2263	2254	2185	2269	2241	2233
				2198	2235	2255	2216	2247	2207	2251	2216	2241	2209	2233	2254	2241	2230	2245	2282	2279	2202	2252	2207	2293	2241	2217	2238	2184	2198	2227	2199	2252	2212	2241	2199
				2228	2224	2203	2235	2182	2245	2296	2235	2205	2258	2227	2252	2209	2255	2270	2252	2205	2224	2228	2207	2203	2228	2216	2265	2198	2205	2213	2213	2279	2217	2223	2209
				2210	2254	2224	2237	2252	2224	2233	2251	2233	2279	2227	2252	2224	2263	2200	2252	2205	2265	2266	2220	2216	2227	2226	2262	2273	2259	2248	2241	2228	2224	2216	2254
				2235	2220	2233	2220	2259	2248	2234	2241	2263	2245	2233	2258	2262	2234	2248	2251	2241	2235	2251	2234	2238	2227	2244	2213	2238	2275	2245	2249	2212	2251	2233	2207
				2248	2245	2258	2230	2223	2234	2237	2242	2248	2268	2248	2221	2198	2255	2231	2234	2219	2234	2216	2256	2240	2198	2261	2205	2254	2248	2210	2234	2234	2261	2242	2242
				3840 3840 3840>;

			PS_Config_Lmt_FW_Rawdata_N = <
				942	966	962	955	952	957	949	959	958	956	956	958	951	963	950	947	963	956	962	947	967	960	957	961	951	961	948	954	960	955	952	949
				969	971	960	961	965	962	961	972	963	945	957	961	960	970	967	973	939	974	981	958	954	959	954	959	951	961	984	964	941	957	930	953
				957	949	951	969	964	962	957	935	969	954	946	952	953	955	944	943	965	967	975	943	972	966	962	950	936	952	955	961	933	976	973	947
				957	960	961	945	960	955	949	952	942	964	965	937	946	952	940	951	964	967	972	939	963	953	937	958	963	963	963	967	943	968	943	961
				962	942	965	948	949	973	964	951	952	952	964	967	936	931	962	964	955	952	954	956	957	948	955	940	952	951	969	946	939	962	954	948
				964	961	951	952	960	969	966	966	945	949	953	955	972	971	960	951	957	952	963	947	958	969	955	966	958	945	967	946	962	948	944	953
				955	942	961	952	946	962	957	975	969	967	969	946	957	972	971	967	947	963	958	949	949	964	972	948	958	949	958	951	957	962	957	976
				957	973	945	952	952	956	952	957	952	946	945	983	955	960	965	960	946	965	951	952	951	964	945	958	948	953	958	957	948	954	949	955
				945	961	954	948	961	976	969	952	971	960	952	963	972	957	955	946	975	958	945	952	970	951	955	963	960	973	954	964	955	941	950	960
				964	939	966	949	953	959	964	959	976	962	957	951	958	952	964	949	976	963	947	942	970	969	968	955	967	957	956	960	946	958	952	944
				958	947	966	960	943	946	960	951	949	954	956	969	945	951	969	966	955	969	952	951	954	948	959	966	956	952	964	966	964	940	962	960
				958	960	951	948	952	951	965	973	960	973	957	957	954	945	976	964	950	961	946	965	945	955	956	958	949	941	959	952	955	973	951	954
				957	961	954	966	970	954	966	956	961	953	941	967	960	964	941	946	947	953	962	964	952	949	958	970	961	970	948	942	948	959	954	951
				951	960	954	954	966	958	967	961	965	955	976	943	963	961	937	945	944	954	954	972	943	969	961	951	960	934	957	940	954	955	954	960
				961	958	970	973	956	951	958	957	967	960	940	954	965	958	945	954	958	964	958	959	958	965	960	961	946	952	957	964	966	963	952	948
				967	954	949	963	946	952	951	966	943	963	969	961	961	961	939	953	952	958	951	962	950	954	948	968	964	963	967	952	951	969	963	961
				966	952	947	949	961	970	958	961	973	964	960	967	970	964	948	953	954	979	956	939	947	969	961	973	960	957	954	964	964	963	961	967
				944	966	967	967	961	972	958	970	938	954	964	950	963	966	956	951	955	976	948	957	966	958	955	951	952	965	957	960	960	935	946	963
				966	961	937	964	957	963	973	948	964	963	960	960	964	954	955	941	956	950	958	966	952	948	952	947	974	975	958	966	946	957	958	954
				947	960	984	941	946	963	958	963	958	951	955	940	958	952	960	947	957	961	960	952	959	970	963	953	951	954	951	955	958	966	950	963
				966	964	959	966	971	958	959	952	968	956	954	961	973	950	975	949	963	970	951	964	962	964	964	956	965	944	963	963	966	961	966	957
				951	955	975	956	967	963	958	957	953	958	960	942	967	959	963	944	952	966	959	958	965	938	954	981	951	952	956	973	961	952	956	955
				949	959	939	960	951	946	970	955	954	954	952	958	960	962	977	956	961	969	959	952	972	970	953	956	952	957	949	969	969	948	961	950
				966	953	979	949	969	954	975	965	952	963	959	951	958	954	964	954	949	976	954	955	947	957	961	966	963	966	949	962	954	957	951	957
				970	959	955	948	964	958	957	942	953	954	953	946	953	972	956	970	947	948	968	966	961	949	960	958	958	945	972	949	943	962	947	949
				957	954	964	968	972	957	947	940	960	951	959	961	953	951	953	969	933	958	952	963	949	967	943	943	957	949	968	959	944	956	975	958
				958	978	971	954	960	948	957	940	960	966	961	941	951	959	943	946	961	959	940	956	970	963	946	964	976	952	969	957	967	957	958	949
				957	948	951	940	969	944	964	952	963	947	946	979	960	955	948	964	959	954	975	946	954	952	957	951	967	954	973	955	962	957	963	966
				948	954	960	957	949	963	969	958	953	957	969	951	957	945	963	958	948	963	949	950	953	973	960	951	949	955	964	972	963	969	957	955
				955	963	948	947	953	961	974	955	956	971	948	966	954	967	947	964	970	952	951	934	963	945	961	969	963	958	971	965	957	937	954	959
				949	960	942	945	951	963	973	965	950	950	957	967	939	935	958	958	970	968	960	946	964	972	963	946	972	967	967	959	952	952	943	942
				951	961	976	964	945	957	977	966	962	973	959	953	972	969	953	951	958	966	952	968	963	957	955	961	967	969	963	943	975	950	981	977
				954	974	954	966	946	961	955	964	937	952	954	955	950	945	942	959	952	956	960	967	968	969	957	965	964	958	958	951	969	960	949	962
				958	942	964	959	947	951	953	958	956	972	970	954	970	977	964	958	950	956	946	955	946	957	970	948	968	957	954	950	961	960	949	964
				948	961	952	952	965	954	954	967	953	957	936	964	950	952	966	961	968	952	958	949	945	968	966	957	960	958	960	955	958	948	951	960
				946	953	970	978	962	948	961	948	957	954	960	949	964	951	954	937	963	945	948	945	967	959	957	966	955	951	949	955	949	963	969	966
				970	956	948	966	943	963	945	969	965	940	958	963	963	949	949	969	942	952	960	947	960	955	941	945	951	954	961	949	963	963	965	967
				957	956	975	944	969	959	952	966	963	955	957	952	945	964	958	948	975	963	969	965	963	951	952	955	954	961	949	970	958	955	965	947
				957	950	957	958	949	958	944	946	951	963	939	949	968	946	975	960	939	963	961	949	961	962	963	950	958	955	971	960	948	959	949	963
				963	969	945	953	944	964	957	955	939	963	955	958	955	966	948	955	974	956	960	964	961	952	961	960	957	955	954	960	962	963	962	958
				958	952	966	961	969	959	969	966	973	963	973	960	966	968	943	961	949	955	954	945	963	962	955	948	962	949	952	970	961	965	949	955
				957	971	960	960	961	957	958	963	972	956	946	948	947	948	950	961	961	955	957	964	949	963	958	952	966	936	964	949	960	946	964	962
				976	958	963	942	961	949	964	946	973	968	957	945	967	961	943	954	965	964	976	947	964	965	970	948	963	959	950	955	957	958	951	943
				957	958	955	976	954	966	952	950	973	966	960	960	949	960	966	960	947	951	945	960	945	970	973	945	971	951	966	958	967	954	960	969
				946	948	954	964	963	952	960	942	957	945	955	953	949	956	957	940	934	967	948	957	956	977	947	958	949	963	970	966	936	972	960	957
				942	958	966	949	963	946	964	949	960	946	957	966	960	955	962	978	976	943	965	946	982	960	950	959	936	942	954	942	965	948	960	942
				955	953	944	958	935	962	984	958	945	967	954	965	946	966	973	965	945	953	955	946	944	955	949	970	942	945	948	948	976	950	952	946
				947	966	953	958	965	953	957	964	957	976	954	965	953	970	943	965	945	970	971	951	949	954	954	969	974	968	963	960	955	953	949	966
				958	951	957	951	968	963	957	960	970	962	957	967	969	957	963	964	960	958	964	957	959	954	961	948	959	975	962	964	948	964	957	946
				963	962	967	955	952	957	958	961	963	972	963	952	942	966	956	957	951	957	949	967	960	942	969	945	966	963	947	957	957	969	961	961
				240 240 240>;

			PS_Config_Lmt_FW_CC_P = <
				106	104	104	104	103	104	103	104	103	104	104	104	103	104	104	104	106	106	104	106	106	106	104	106	104	104	104	106	106	106	104	107
				104	102	102	103	100	102	102	102	102	103	103	103	102	103	103	103	106	104	103	104	104	104	103	104	103	103	102	103	103	103	103	104
				104	104	104	104	103	104	103	104	103	104	104	104	103	104	104	104	106	106	104	106	106	106	104	104	106	104	104	104	106	106	104	106
				104	103	102	103	102	103	102	103	103	103	103	104	103	104	104	104	106	106	104	106	106	104	104	104	104	103	103	103	104	103	103	104
				104	103	102	103	102	102	102	103	103	103	103	103	103	103	103	103	103	104	103	103	103	104	103	103	103	103	103	103	103	103	103	104
				103	100	100	100	100	100	100	102	102	102	102	102	102	102	102	103	103	103	103	103	103	103	103	102	102	102	102	102	102	102	102	102
				106	104	104	104	104	103	103	103	103	103	103	104	104	103	103	103	104	106	104	106	104	106	104	106	104	106	104	106	104	106	106	107
				106	102	102	103	103	103	102	102	103	103	103	103	103	103	103	103	104	106	104	104	104	106	103	104	103	104	103	104	103	104	103	104
				104	104	104	104	103	103	103	104	103	104	104	104	104	104	104	104	106	106	104	104	106	106	104	104	104	104	104	104	104	106	106	106
				104	103	102	103	102	103	102	103	103	103	103	104	104	104	104	104	104	106	104	104	104	104	104	104	104	104	103	103	103	104	103	104
				104	103	102	102	103	103	102	102	103	103	103	102	103	103	103	102	103	103	103	104	103	103	103	103	103	103	103	104	103	103	103	104
				103	100	100	100	100	102	100	100	102	102	102	102	102	103	102	102	103	103	103	104	103	103	103	103	102	102	102	103	102	100	102	103
				104	104	103	103	103	103	102	103	103	103	103	103	103	103	103	103	104	104	104	104	104	104	104	103	104	104	104	104	106	104	106	106
				104	102	102	102	102	102	100	102	102	103	102	103	103	103	103	103	104	104	103	104	104	104	103	103	103	103	103	103	103	103	103	103
				104	104	104	104	103	104	103	104	103	104	104	104	103	103	104	104	104	104	104	106	104	106	104	104	104	104	104	104	104	106	106	106
				103	103	102	103	102	102	102	103	103	103	103	104	103	103	104	104	104	104	104	104	104	104	104	104	103	103	103	103	103	104	103	104
				103	103	102	103	102	102	102	103	102	102	103	103	102	102	103	102	102	103	103	104	103	103	103	103	103	103	103	103	103	103	103	104
				103	100	100	100	100	100	100	102	100	102	102	102	102	102	102	102	102	103	103	103	102	103	102	103	102	102	100	102	100	102	102	103
				103	103	103	103	102	103	102	103	103	103	103	103	103	103	103	103	104	103	104	103	104	103	104	103	104	103	104	103	104	103	104	104
				103	102	100	102	100	102	102	102	102	102	102	103	102	102	102	103	104	103	104	103	103	103	103	102	103	102	103	102	103	102	103	103
				104	106	104	104	103	104	103	103	103	104	103	103	103	104	103	103	103	104	104	103	103	104	104	103	103	103	104	104	104	104	106	106
				104	103	102	102	102	103	102	102	102	103	103	103	103	103	103	103	103	103	104	103	103	103	103	102	103	102	103	103	103	103	104	104
				104	106	104	104	104	104	104	104	103	104	104	104	103	104	104	103	104	104	104	106	104	104	104	104	104	104	104	104	104	106	104	106
				103	103	103	103	102	103	103	103	103	103	104	103	103	104	104	103	104	104	103	104	104	104	103	104	103	103	103	103	103	103	103	104
				103	102	103	103	102	102	103	103	102	102	103	103	102	102	103	102	103	103	103	103	103	103	103	103	103	102	103	103	103	103	104	104
				103	100	100	100	100	100	102	102	102	100	102	102	102	100	102	102	102	102	103	102	102	102	103	102	102	100	102	102	100	100	102	103
				104	103	103	103	103	103	103	103	103	103	103	103	103	103	103	103	103	104	103	103	103	104	104	103	103	103	103	103	103	104	104	104
				103	102	102	102	100	102	102	102	102	102	103	103	103	102	103	103	103	103	103	103	103	103	103	102	102	102	102	100	102	102	103	104
				106	104	104	104	104	103	103	103	103	103	103	103	103	103	103	103	104	103	103	103	104	103	103	103	104	103	103	104	104	104	104	106
				104	102	103	103	102	102	102	102	103	102	103	103	103	102	103	103	103	103	103	103	103	103	102	102	103	102	102	102	103	103	103	106
				106	104	104	104	103	104	103	103	104	103	104	103	103	103	103	103	103	103	104	104	104	103	104	104	103	103	104	104	104	104	106	106
				104	103	102	102	102	103	102	103	103	103	103	103	103	103	103	103	103	103	104	103	103	103	104	103	103	102	103	103	103	103	103	104
				103	102	102	103	102	102	102	102	102	102	102	103	102	102	102	102	102	102	103	102	102	102	103	102	102	102	103	103	102	103	104	104
				102	100	99	100	100	100	100	102	100	100	100	102	102	100	100	102	102	102	103	102	102	102	102	102	100	100	102	100	100	100	102	104
				104	102	103	103	103	102	103	103	103	102	103	103	103	102	102	103	103	104	103	103	104	104	103	103	103	104	103	103	104	104	103	104
				103	100	102	102	100	100	100	102	102	100	102	103	102	100	102	103	103	103	102	103	103	103	102	102	102	103	100	100	102	103	102	104
				104	103	104	103	104	102	103	103	103	102	103	103	103	102	102	102	103	103	103	103	104	103	103	103	104	103	103	103	104	104	104	106
				103	100	102	102	102	100	102	102	102	100	102	102	102	100	102	102	103	103	102	102	103	103	102	102	103	102	102	102	103	103	103	106
				104	104	104	104	103	103	103	103	103	103	103	103	103	103	103	103	104	103	104	104	104	104	104	104	104	103	104	104	104	104	106	106
				103	102	102	102	102	102	102	102	102	102	103	103	102	102	103	103	103	103	103	103	103	103	103	103	103	102	103	102	103	103	103	106
				103	103	102	102	102	102	102	100	102	102	102	100	102	102	102	100	102	102	102	102	102	102	102	102	102	102	102	103	102	102	103	104
				100	100	100	99	100	100	100	99	100	100	100	100	100	100	100	100	102	100	100	102	102	100	100	100	100	100	100	100	100	100	100	104
				103	103	103	102	102	103	102	102	102	102	102	102	102	102	102	102	103	103	103	102	103	103	103	102	103	103	103	102	103	104	104	106
				100	100	100	99	99	100	100	100	100	100	102	100	100	100	102	100	102	102	103	102	102	102	102	100	102	102	102	100	102	102	102	104
				104	104	104	103	103	103	103	102	102	102	103	102	102	102	103	102	103	103	103	103	103	103	103	103	103	102	104	104	104	104	106	106
				102	102	102	100	100	100	100	100	100	102	102	102	102	102	102	102	102	102	103	102	102	102	102	102	102	100	102	102	102	102	103	106
				104	104	104	103	103	103	103	103	103	103	103	103	103	103	103	103	104	103	104	103	104	103	104	103	104	103	104	103	104	104	106	106
				102	102	102	100	100	102	102	100	100	102	102	102	102	102	103	102	103	102	103	102	103	102	103	102	102	102	102	102	103	102	103	104
				103	102	102	102	102	102	102	102	102	102	102	102	102	100	102	102	102	102	102	102	103	102	102	102	102	102	102	102	103	103	103	106
				100	99	99	100	100	99	100	100	100	100	100	102	102	100	100	102	102	102	100	100	102	100	100	100	100	100	100	99	100	100	100	104
				314 314 314>;

			PS_Config_Lmt_FW_CC_N = <
				47	47	47	47	46	47	46	47	46	47	47	47	46	47	47	47	47	47	47	47	47	47	47	47	47	47	47	47	47	47	47	48
				47	45	45	46	45	45	45	45	45	46	46	46	45	46	46	46	47	47	46	47	47	47	46	47	46	46	45	46	46	46	46	47
				47	47	47	47	46	47	46	47	46	47	47	47	46	47	47	47	47	47	47	47	47	47	47	47	47	47	47	47	47	47	47	47
				47	46	45	46	45	46	45	46	46	46	46	47	46	47	47	47	47	47	47	47	47	47	47	47	47	46	46	46	47	46	46	47
				47	46	45	46	45	45	45	46	46	46	46	46	46	46	46	46	46	47	46	46	46	47	46	46	46	46	46	46	46	46	46	47
				46	45	45	45	45	45	45	45	45	45	45	45	45	45	45	46	46	46	46	46	46	46	46	45	45	45	45	45	45	45	45	45
				47	47	47	47	47	46	46	46	46	46	46	47	47	46	46	46	47	47	47	47	47	47	47	47	47	47	47	47	47	47	47	48
				47	45	45	46	46	46	45	45	46	46	46	46	46	46	46	46	47	47	47	47	47	47	46	47	46	47	46	47	46	47	46	47
				47	47	47	47	46	46	46	47	46	47	47	47	47	47	47	47	47	47	47	47	47	47	47	47	47	47	47	47	47	47	47	47
				47	46	45	46	45	46	45	46	46	46	46	47	47	47	47	47	47	47	47	47	47	47	47	47	47	47	46	46	46	47	46	47
				47	46	45	45	46	46	45	45	46	46	46	45	46	46	46	45	46	46	46	47	46	46	46	46	46	46	46	47	46	46	46	47
				46	45	45	45	45	45	45	45	45	45	45	45	45	46	45	45	46	46	46	47	46	46	46	46	45	45	45	46	45	45	45	46
				47	47	46	46	46	46	45	46	46	46	46	46	46	46	46	46	47	47	47	47	47	47	47	46	47	47	47	47	47	47	47	47
				47	45	45	45	45	45	45	45	45	46	45	46	46	46	46	46	47	47	46	47	47	47	46	46	46	46	46	46	46	46	46	46
				47	47	47	47	46	47	46	47	46	47	47	47	46	46	47	47	47	47	47	47	47	47	47	47	47	47	47	47	47	47	47	47
				46	46	45	46	45	45	45	46	46	46	46	47	46	46	47	47	47	47	47	47	47	47	47	47	46	46	46	46	46	47	46	47
				46	46	45	46	45	45	45	46	45	45	46	46	45	45	46	45	45	46	46	47	46	46	46	46	46	46	46	46	46	46	46	47
				46	45	45	45	45	45	45	45	45	45	45	45	45	45	45	45	45	46	46	46	45	46	45	46	45	45	45	45	45	45	45	46
				46	46	46	46	45	46	45	46	46	46	46	46	46	46	46	46	47	46	47	46	47	46	47	46	47	46	47	46	47	46	47	47
				46	45	45	45	45	45	45	45	45	45	45	46	45	45	45	46	47	46	47	46	46	46	46	45	46	45	46	45	46	45	46	46
				47	47	47	47	46	47	46	46	46	47	46	46	46	47	46	46	46	47	47	46	46	47	47	46	46	46	47	47	47	47	47	47
				47	46	45	45	45	46	45	45	45	46	46	46	46	46	46	46	46	46	47	46	46	46	46	45	46	45	46	46	46	46	47	47
				47	47	47	47	47	47	47	47	46	47	47	47	46	47	47	46	47	47	47	47	47	47	47	47	47	47	47	47	47	47	47	47
				46	46	46	46	45	46	46	46	46	46	47	46	46	47	47	46	47	47	46	47	47	47	46	47	46	46	46	46	46	46	46	47
				46	45	46	46	45	45	46	46	45	45	46	46	45	45	46	45	46	46	46	46	46	46	46	46	46	45	46	46	46	46	47	47
				46	45	45	45	45	45	45	45	45	45	45	45	45	45	45	45	45	45	46	45	45	45	46	45	45	45	45	45	45	45	45	46
				47	46	46	46	46	46	46	46	46	46	46	46	46	46	46	46	46	47	46	46	46	47	47	46	46	46	46	46	46	47	47	47
				46	45	45	45	45	45	45	45	45	45	46	46	46	45	46	46	46	46	46	46	46	46	46	45	45	45	45	45	45	45	46	47
				47	47	47	47	47	46	46	46	46	46	46	46	46	46	46	46	47	46	46	46	47	46	46	46	47	46	46	47	47	47	47	47
				47	45	46	46	45	45	45	45	46	45	46	46	46	45	46	46	46	46	46	46	46	46	45	45	46	45	45	45	46	46	46	47
				47	47	47	47	46	47	46	46	47	46	47	46	46	46	46	46	46	46	47	47	47	46	47	47	46	46	47	47	47	47	47	47
				47	46	45	45	45	46	45	46	46	46	46	46	46	46	46	46	46	46	47	46	46	46	47	46	46	45	46	46	46	46	46	47
				46	45	45	46	45	45	45	45	45	45	45	46	45	45	45	45	45	45	46	45	45	45	46	45	45	45	46	46	45	46	47	47
				45	45	44	45	45	45	45	45	45	45	45	45	45	45	45	45	45	45	46	45	45	45	45	45	45	45	45	45	45	45	45	47
				47	45	46	46	46	45	46	46	46	45	46	46	46	45	45	46	46	47	46	46	47	47	46	46	46	47	46	46	47	47	46	47
				46	45	45	45	45	45	45	45	45	45	45	46	45	45	45	46	46	46	45	46	46	46	45	45	45	46	45	45	45	46	45	47
				47	46	47	46	47	45	46	46	46	45	46	46	46	45	45	45	46	46	46	46	47	46	46	46	47	46	46	46	47	47	47	47
				46	45	45	45	45	45	45	45	45	45	45	45	45	45	45	45	46	46	45	45	46	46	45	45	46	45	45	45	46	46	46	47
				47	47	47	47	46	46	46	46	46	46	46	46	46	46	46	46	47	46	47	47	47	47	47	47	47	46	47	47	47	47	47	47
				46	45	45	45	45	45	45	45	45	45	46	46	45	45	46	46	46	46	46	46	46	46	46	46	46	45	46	45	46	46	46	47
				46	46	45	45	45	45	45	45	45	45	45	45	45	45	45	45	45	45	45	45	45	45	45	45	45	45	45	46	45	45	46	47
				45	45	45	44	45	45	45	44	45	45	45	45	45	45	45	45	45	45	45	45	45	45	45	45	45	45	45	45	45	45	45	47
				46	46	46	45	45	46	45	45	45	45	45	45	45	45	45	45	46	46	46	45	46	46	46	45	46	46	46	45	46	47	47	47
				45	45	45	44	44	45	45	45	45	45	45	45	45	45	45	45	45	45	46	45	45	45	45	45	45	45	45	45	45	45	45	47
				47	47	47	46	46	46	46	45	45	45	46	45	45	45	46	45	46	46	46	46	46	46	46	46	46	45	47	47	47	47	47	47
				45	45	45	45	45	45	45	45	45	45	45	45	45	45	45	45	45	45	46	45	45	45	45	45	45	45	45	45	45	45	46	47
				47	47	47	46	46	46	46	46	46	46	46	46	46	46	46	46	47	46	47	46	47	46	47	46	47	46	47	46	47	47	47	47
				45	45	45	45	45	45	45	45	45	45	45	45	45	45	46	45	46	45	46	45	46	45	46	45	45	45	45	45	46	45	46	47
				46	45	45	45	45	45	45	45	45	45	45	45	45	45	45	45	45	45	45	45	46	45	45	45	45	45	45	45	46	46	46	47
				45	44	44	45	45	44	45	45	45	45	45	45	45	45	45	45	45	45	45	45	45	45	45	45	45	45	45	44	45	45	45	47
				0 0 0>;

			PS_Config_Lmt_FW_Diff_P = <
				80	80	80	80	80	80	80	80	80	80	80	80	80	80	80	80	80	80	80	80	80	80	80	80	80	80	80	80	80	80	80	80
				80	80	80	80	80	80	80	80	80	80	80	80	80	80	80	80	80	80	80	80	80	80	80	80	80	80	80	80	80	80	80	80
				80	80	80	80	80	80	80	80	80	80	80	80	80	80	80	80	80	80	80	80	80	80	80	80	80	80	80	80	80	80	80	80
				80	80	80	80	80	80	80	80	80	80	80	80	80	80	80	80	80	80	80	80	80	80	80	80	80	80	80	80	80	80	80	80
				80	80	80	80	80	80	80	80	80	80	80	80	80	80	80	80	80	80	80	80	80	80	80	80	80	80	80	80	80	80	80	80
				80	80	80	80	80	80	80	80	80	80	80	80	80	80	80	80	80	80	80	80	80	80	80	80	80	80	80	80	80	80	80	80
				80	80	80	80	80	80	80	80	80	80	80	80	80	80	80	80	80	80	80	80	80	80	80	80	80	80	80	80	80	80	80	80
				80	80	80	80	80	80	80	80	80	80	80	80	80	80	80	80	80	80	80	80	80	80	80	80	80	80	80	80	80	80	80	80
				80	80	80	80	80	80	80	80	80	80	80	80	80	80	80	80	80	80	80	80	80	80	80	80	80	80	80	80	80	80	80	80
				80	80	80	80	80	80	80	80	80	80	80	80	80	80	80	80	80	80	80	80	80	80	80	80	80	80	80	80	80	80	80	80
				80	80	80	80	80	80	80	80	80	80	80	80	80	80	80	80	80	80	80	80	80	80	80	80	80	80	80	80	80	80	80	80
				80	80	80	80	80	80	80	80	80	80	80	80	80	80	80	80	80	80	80	80	80	80	80	80	80	80	80	80	80	80	80	80
				80	80	80	80	80	80	80	80	80	80	80	80	80	80	80	80	80	80	80	80	80	80	80	80	80	80	80	80	80	80	80	80
				80	80	80	80	80	80	80	80	80	80	80	80	80	80	80	80	80	80	80	80	80	80	80	80	80	80	80	80	80	80	80	80
				80	80	80	80	80	80	80	80	80	80	80	80	80	80	80	80	80	80	80	80	80	80	80	80	80	80	80	80	80	80	80	80
				80	80	80	80	80	80	80	80	80	80	80	80	80	80	80	80	80	80	80	80	80	80	80	80	80	80	80	80	80	80	80	80
				80	80	80	80	80	80	80	80	80	80	80	80	80	80	80	80	80	80	80	80	80	80	80	80	80	80	80	80	80	80	80	80
				80	80	80	80	80	80	80	80	80	80	80	80	80	80	80	80	80	80	80	80	80	80	80	80	80	80	80	80	80	80	80	80
				80	80	80	80	80	80	80	80	80	80	80	80	80	80	80	80	80	80	80	80	80	80	80	80	80	80	80	80	80	80	80	80
				80	80	80	80	80	80	80	80	80	80	80	80	80	80	80	80	80	80	80	80	80	80	80	80	80	80	80	80	80	80	80	80
				80	80	80	80	80	80	80	80	80	80	80	80	80	80	80	80	80	80	80	80	80	80	80	80	80	80	80	80	80	80	80	80
				80	80	80	80	80	80	80	80	80	80	80	80	80	80	80	80	80	80	80	80	80	80	80	80	80	80	80	80	80	80	80	80
				80	80	80	80	80	80	80	80	80	80	80	80	80	80	80	80	80	80	80	80	80	80	80	80	80	80	80	80	80	80	80	80
				80	80	80	80	80	80	80	80	80	80	80	80	80	80	80	80	80	80	80	80	80	80	80	80	80	80	80	80	80	80	80	80
				80	80	80	80	80	80	80	80	80	80	80	80	80	80	80	80	80	80	80	80	80	80	80	80	80	80	80	80	80	80	80	80
				80	80	80	80	80	80	80	80	80	80	80	80	80	80	80	80	80	80	80	80	80	80	80	80	80	80	80	80	80	80	80	80
				80	80	80	80	80	80	80	80	80	80	80	80	80	80	80	80	80	80	80	80	80	80	80	80	80	80	80	80	80	80	80	80
				80	80	80	80	80	80	80	80	80	80	80	80	80	80	80	80	80	80	80	80	80	80	80	80	80	80	80	80	80	80	80	80
				80	80	80	80	80	80	80	80	80	80	80	80	80	80	80	80	80	80	80	80	80	80	80	80	80	80	80	80	80	80	80	80
				80	80	80	80	80	80	80	80	80	80	80	80	80	80	80	80	80	80	80	80	80	80	80	80	80	80	80	80	80	80	80	80
				80	80	80	80	80	80	80	80	80	80	80	80	80	80	80	80	80	80	80	80	80	80	80	80	80	80	80	80	80	80	80	80
				80	80	80	80	80	80	80	80	80	80	80	80	80	80	80	80	80	80	80	80	80	80	80	80	80	80	80	80	80	80	80	80
				80	80	80	80	80	80	80	80	80	80	80	80	80	80	80	80	80	80	80	80	80	80	80	80	80	80	80	80	80	80	80	80
				80	80	80	80	80	80	80	80	80	80	80	80	80	80	80	80	80	80	80	80	80	80	80	80	80	80	80	80	80	80	80	80
				80	80	80	80	80	80	80	80	80	80	80	80	80	80	80	80	80	80	80	80	80	80	80	80	80	80	80	80	80	80	80	80
				80	80	80	80	80	80	80	80	80	80	80	80	80	80	80	80	80	80	80	80	80	80	80	80	80	80	80	80	80	80	80	80
				80	80	80	80	80	80	80	80	80	80	80	80	80	80	80	80	80	80	80	80	80	80	80	80	80	80	80	80	80	80	80	80
				80	80	80	80	80	80	80	80	80	80	80	80	80	80	80	80	80	80	80	80	80	80	80	80	80	80	80	80	80	80	80	80
				80	80	80	80	80	80	80	80	80	80	80	80	80	80	80	80	80	80	80	80	80	80	80	80	80	80	80	80	80	80	80	80
				80	80	80	80	80	80	80	80	80	80	80	80	80	80	80	80	80	80	80	80	80	80	80	80	80	80	80	80	80	80	80	80
				80	80	80	80	80	80	80	80	80	80	80	80	80	80	80	80	80	80	80	80	80	80	80	80	80	80	80	80	80	80	80	80
				80	80	80	80	80	80	80	80	80	80	80	80	80	80	80	80	80	80	80	80	80	80	80	80	80	80	80	80	80	80	80	80
				80	80	80	80	80	80	80	80	80	80	80	80	80	80	80	80	80	80	80	80	80	80	80	80	80	80	80	80	80	80	80	80
				80	80	80	80	80	80	80	80	80	80	80	80	80	80	80	80	80	80	80	80	80	80	80	80	80	80	80	80	80	80	80	80
				80	80	80	80	80	80	80	80	80	80	80	80	80	80	80	80	80	80	80	80	80	80	80	80	80	80	80	80	80	80	80	80
				80	80	80	80	80	80	80	80	80	80	80	80	80	80	80	80	80	80	80	80	80	80	80	80	80	80	80	80	80	80	80	80
				80	80	80	80	80	80	80	80	80	80	80	80	80	80	80	80	80	80	80	80	80	80	80	80	80	80	80	80	80	80	80	80
				80	80	80	80	80	80	80	80	80	80	80	80	80	80	80	80	80	80	80	80	80	80	80	80	80	80	80	80	80	80	80	80
				80	80	80	80	80	80	80	80	80	80	80	80	80	80	80	80	80	80	80	80	80	80	80	80	80	80	80	80	80	80	80	80
				80	80	80	80	80	80	80	80	80	80	80	80	80	80	80	80	80	80	80	80	80	80	80	80	80	80	80	80	80	80	80	80
				75 75 75>;

			PS_Config_Lmt_FW_Diff_N = <
				(-80)	(-80)	(-80)	(-80)	(-80)	(-80)	(-80)	(-80)	(-80)	(-80)	(-80)	(-80)	(-80)	(-80)	(-80)	(-80)	(-80)	(-80)	(-80)	(-80)	(-80)	(-80)	(-80)	(-80)	(-80)	(-80)	(-80)	(-80)	(-80)	(-80)	(-80)	(-80)
				(-80)	(-80)	(-80)	(-80)	(-80)	(-80)	(-80)	(-80)	(-80)	(-80)	(-80)	(-80)	(-80)	(-80)	(-80)	(-80)	(-80)	(-80)	(-80)	(-80)	(-80)	(-80)	(-80)	(-80)	(-80)	(-80)	(-80)	(-80)	(-80)	(-80)	(-80)	(-80)
				(-80)	(-80)	(-80)	(-80)	(-80)	(-80)	(-80)	(-80)	(-80)	(-80)	(-80)	(-80)	(-80)	(-80)	(-80)	(-80)	(-80)	(-80)	(-80)	(-80)	(-80)	(-80)	(-80)	(-80)	(-80)	(-80)	(-80)	(-80)	(-80)	(-80)	(-80)	(-80)
				(-80)	(-80)	(-80)	(-80)	(-80)	(-80)	(-80)	(-80)	(-80)	(-80)	(-80)	(-80)	(-80)	(-80)	(-80)	(-80)	(-80)	(-80)	(-80)	(-80)	(-80)	(-80)	(-80)	(-80)	(-80)	(-80)	(-80)	(-80)	(-80)	(-80)	(-80)	(-80)
				(-80)	(-80)	(-80)	(-80)	(-80)	(-80)	(-80)	(-80)	(-80)	(-80)	(-80)	(-80)	(-80)	(-80)	(-80)	(-80)	(-80)	(-80)	(-80)	(-80)	(-80)	(-80)	(-80)	(-80)	(-80)	(-80)	(-80)	(-80)	(-80)	(-80)	(-80)	(-80)
				(-80)	(-80)	(-80)	(-80)	(-80)	(-80)	(-80)	(-80)	(-80)	(-80)	(-80)	(-80)	(-80)	(-80)	(-80)	(-80)	(-80)	(-80)	(-80)	(-80)	(-80)	(-80)	(-80)	(-80)	(-80)	(-80)	(-80)	(-80)	(-80)	(-80)	(-80)	(-80)
				(-80)	(-80)	(-80)	(-80)	(-80)	(-80)	(-80)	(-80)	(-80)	(-80)	(-80)	(-80)	(-80)	(-80)	(-80)	(-80)	(-80)	(-80)	(-80)	(-80)	(-80)	(-80)	(-80)	(-80)	(-80)	(-80)	(-80)	(-80)	(-80)	(-80)	(-80)	(-80)
				(-80)	(-80)	(-80)	(-80)	(-80)	(-80)	(-80)	(-80)	(-80)	(-80)	(-80)	(-80)	(-80)	(-80)	(-80)	(-80)	(-80)	(-80)	(-80)	(-80)	(-80)	(-80)	(-80)	(-80)	(-80)	(-80)	(-80)	(-80)	(-80)	(-80)	(-80)	(-80)
				(-80)	(-80)	(-80)	(-80)	(-80)	(-80)	(-80)	(-80)	(-80)	(-80)	(-80)	(-80)	(-80)	(-80)	(-80)	(-80)	(-80)	(-80)	(-80)	(-80)	(-80)	(-80)	(-80)	(-80)	(-80)	(-80)	(-80)	(-80)	(-80)	(-80)	(-80)	(-80)
				(-80)	(-80)	(-80)	(-80)	(-80)	(-80)	(-80)	(-80)	(-80)	(-80)	(-80)	(-80)	(-80)	(-80)	(-80)	(-80)	(-80)	(-80)	(-80)	(-80)	(-80)	(-80)	(-80)	(-80)	(-80)	(-80)	(-80)	(-80)	(-80)	(-80)	(-80)	(-80)
				(-80)	(-80)	(-80)	(-80)	(-80)	(-80)	(-80)	(-80)	(-80)	(-80)	(-80)	(-80)	(-80)	(-80)	(-80)	(-80)	(-80)	(-80)	(-80)	(-80)	(-80)	(-80)	(-80)	(-80)	(-80)	(-80)	(-80)	(-80)	(-80)	(-80)	(-80)	(-80)
				(-80)	(-80)	(-80)	(-80)	(-80)	(-80)	(-80)	(-80)	(-80)	(-80)	(-80)	(-80)	(-80)	(-80)	(-80)	(-80)	(-80)	(-80)	(-80)	(-80)	(-80)	(-80)	(-80)	(-80)	(-80)	(-80)	(-80)	(-80)	(-80)	(-80)	(-80)	(-80)
				(-80)	(-80)	(-80)	(-80)	(-80)	(-80)	(-80)	(-80)	(-80)	(-80)	(-80)	(-80)	(-80)	(-80)	(-80)	(-80)	(-80)	(-80)	(-80)	(-80)	(-80)	(-80)	(-80)	(-80)	(-80)	(-80)	(-80)	(-80)	(-80)	(-80)	(-80)	(-80)
				(-80)	(-80)	(-80)	(-80)	(-80)	(-80)	(-80)	(-80)	(-80)	(-80)	(-80)	(-80)	(-80)	(-80)	(-80)	(-80)	(-80)	(-80)	(-80)	(-80)	(-80)	(-80)	(-80)	(-80)	(-80)	(-80)	(-80)	(-80)	(-80)	(-80)	(-80)	(-80)
				(-80)	(-80)	(-80)	(-80)	(-80)	(-80)	(-80)	(-80)	(-80)	(-80)	(-80)	(-80)	(-80)	(-80)	(-80)	(-80)	(-80)	(-80)	(-80)	(-80)	(-80)	(-80)	(-80)	(-80)	(-80)	(-80)	(-80)	(-80)	(-80)	(-80)	(-80)	(-80)
				(-80)	(-80)	(-80)	(-80)	(-80)	(-80)	(-80)	(-80)	(-80)	(-80)	(-80)	(-80)	(-80)	(-80)	(-80)	(-80)	(-80)	(-80)	(-80)	(-80)	(-80)	(-80)	(-80)	(-80)	(-80)	(-80)	(-80)	(-80)	(-80)	(-80)	(-80)	(-80)
				(-80)	(-80)	(-80)	(-80)	(-80)	(-80)	(-80)	(-80)	(-80)	(-80)	(-80)	(-80)	(-80)	(-80)	(-80)	(-80)	(-80)	(-80)	(-80)	(-80)	(-80)	(-80)	(-80)	(-80)	(-80)	(-80)	(-80)	(-80)	(-80)	(-80)	(-80)	(-80)
				(-80)	(-80)	(-80)	(-80)	(-80)	(-80)	(-80)	(-80)	(-80)	(-80)	(-80)	(-80)	(-80)	(-80)	(-80)	(-80)	(-80)	(-80)	(-80)	(-80)	(-80)	(-80)	(-80)	(-80)	(-80)	(-80)	(-80)	(-80)	(-80)	(-80)	(-80)	(-80)
				(-80)	(-80)	(-80)	(-80)	(-80)	(-80)	(-80)	(-80)	(-80)	(-80)	(-80)	(-80)	(-80)	(-80)	(-80)	(-80)	(-80)	(-80)	(-80)	(-80)	(-80)	(-80)	(-80)	(-80)	(-80)	(-80)	(-80)	(-80)	(-80)	(-80)	(-80)	(-80)
				(-80)	(-80)	(-80)	(-80)	(-80)	(-80)	(-80)	(-80)	(-80)	(-80)	(-80)	(-80)	(-80)	(-80)	(-80)	(-80)	(-80)	(-80)	(-80)	(-80)	(-80)	(-80)	(-80)	(-80)	(-80)	(-80)	(-80)	(-80)	(-80)	(-80)	(-80)	(-80)
				(-80)	(-80)	(-80)	(-80)	(-80)	(-80)	(-80)	(-80)	(-80)	(-80)	(-80)	(-80)	(-80)	(-80)	(-80)	(-80)	(-80)	(-80)	(-80)	(-80)	(-80)	(-80)	(-80)	(-80)	(-80)	(-80)	(-80)	(-80)	(-80)	(-80)	(-80)	(-80)
				(-80)	(-80)	(-80)	(-80)	(-80)	(-80)	(-80)	(-80)	(-80)	(-80)	(-80)	(-80)	(-80)	(-80)	(-80)	(-80)	(-80)	(-80)	(-80)	(-80)	(-80)	(-80)	(-80)	(-80)	(-80)	(-80)	(-80)	(-80)	(-80)	(-80)	(-80)	(-80)
				(-80)	(-80)	(-80)	(-80)	(-80)	(-80)	(-80)	(-80)	(-80)	(-80)	(-80)	(-80)	(-80)	(-80)	(-80)	(-80)	(-80)	(-80)	(-80)	(-80)	(-80)	(-80)	(-80)	(-80)	(-80)	(-80)	(-80)	(-80)	(-80)	(-80)	(-80)	(-80)
				(-80)	(-80)	(-80)	(-80)	(-80)	(-80)	(-80)	(-80)	(-80)	(-80)	(-80)	(-80)	(-80)	(-80)	(-80)	(-80)	(-80)	(-80)	(-80)	(-80)	(-80)	(-80)	(-80)	(-80)	(-80)	(-80)	(-80)	(-80)	(-80)	(-80)	(-80)	(-80)
				(-80)	(-80)	(-80)	(-80)	(-80)	(-80)	(-80)	(-80)	(-80)	(-80)	(-80)	(-80)	(-80)	(-80)	(-80)	(-80)	(-80)	(-80)	(-80)	(-80)	(-80)	(-80)	(-80)	(-80)	(-80)	(-80)	(-80)	(-80)	(-80)	(-80)	(-80)	(-80)
				(-80)	(-80)	(-80)	(-80)	(-80)	(-80)	(-80)	(-80)	(-80)	(-80)	(-80)	(-80)	(-80)	(-80)	(-80)	(-80)	(-80)	(-80)	(-80)	(-80)	(-80)	(-80)	(-80)	(-80)	(-80)	(-80)	(-80)	(-80)	(-80)	(-80)	(-80)	(-80)
				(-80)	(-80)	(-80)	(-80)	(-80)	(-80)	(-80)	(-80)	(-80)	(-80)	(-80)	(-80)	(-80)	(-80)	(-80)	(-80)	(-80)	(-80)	(-80)	(-80)	(-80)	(-80)	(-80)	(-80)	(-80)	(-80)	(-80)	(-80)	(-80)	(-80)	(-80)	(-80)
				(-80)	(-80)	(-80)	(-80)	(-80)	(-80)	(-80)	(-80)	(-80)	(-80)	(-80)	(-80)	(-80)	(-80)	(-80)	(-80)	(-80)	(-80)	(-80)	(-80)	(-80)	(-80)	(-80)	(-80)	(-80)	(-80)	(-80)	(-80)	(-80)	(-80)	(-80)	(-80)
				(-80)	(-80)	(-80)	(-80)	(-80)	(-80)	(-80)	(-80)	(-80)	(-80)	(-80)	(-80)	(-80)	(-80)	(-80)	(-80)	(-80)	(-80)	(-80)	(-80)	(-80)	(-80)	(-80)	(-80)	(-80)	(-80)	(-80)	(-80)	(-80)	(-80)	(-80)	(-80)
				(-80)	(-80)	(-80)	(-80)	(-80)	(-80)	(-80)	(-80)	(-80)	(-80)	(-80)	(-80)	(-80)	(-80)	(-80)	(-80)	(-80)	(-80)	(-80)	(-80)	(-80)	(-80)	(-80)	(-80)	(-80)	(-80)	(-80)	(-80)	(-80)	(-80)	(-80)	(-80)
				(-80)	(-80)	(-80)	(-80)	(-80)	(-80)	(-80)	(-80)	(-80)	(-80)	(-80)	(-80)	(-80)	(-80)	(-80)	(-80)	(-80)	(-80)	(-80)	(-80)	(-80)	(-80)	(-80)	(-80)	(-80)	(-80)	(-80)	(-80)	(-80)	(-80)	(-80)	(-80)
				(-80)	(-80)	(-80)	(-80)	(-80)	(-80)	(-80)	(-80)	(-80)	(-80)	(-80)	(-80)	(-80)	(-80)	(-80)	(-80)	(-80)	(-80)	(-80)	(-80)	(-80)	(-80)	(-80)	(-80)	(-80)	(-80)	(-80)	(-80)	(-80)	(-80)	(-80)	(-80)
				(-80)	(-80)	(-80)	(-80)	(-80)	(-80)	(-80)	(-80)	(-80)	(-80)	(-80)	(-80)	(-80)	(-80)	(-80)	(-80)	(-80)	(-80)	(-80)	(-80)	(-80)	(-80)	(-80)	(-80)	(-80)	(-80)	(-80)	(-80)	(-80)	(-80)	(-80)	(-80)
				(-80)	(-80)	(-80)	(-80)	(-80)	(-80)	(-80)	(-80)	(-80)	(-80)	(-80)	(-80)	(-80)	(-80)	(-80)	(-80)	(-80)	(-80)	(-80)	(-80)	(-80)	(-80)	(-80)	(-80)	(-80)	(-80)	(-80)	(-80)	(-80)	(-80)	(-80)	(-80)
				(-80)	(-80)	(-80)	(-80)	(-80)	(-80)	(-80)	(-80)	(-80)	(-80)	(-80)	(-80)	(-80)	(-80)	(-80)	(-80)	(-80)	(-80)	(-80)	(-80)	(-80)	(-80)	(-80)	(-80)	(-80)	(-80)	(-80)	(-80)	(-80)	(-80)	(-80)	(-80)
				(-80)	(-80)	(-80)	(-80)	(-80)	(-80)	(-80)	(-80)	(-80)	(-80)	(-80)	(-80)	(-80)	(-80)	(-80)	(-80)	(-80)	(-80)	(-80)	(-80)	(-80)	(-80)	(-80)	(-80)	(-80)	(-80)	(-80)	(-80)	(-80)	(-80)	(-80)	(-80)
				(-80)	(-80)	(-80)	(-80)	(-80)	(-80)	(-80)	(-80)	(-80)	(-80)	(-80)	(-80)	(-80)	(-80)	(-80)	(-80)	(-80)	(-80)	(-80)	(-80)	(-80)	(-80)	(-80)	(-80)	(-80)	(-80)	(-80)	(-80)	(-80)	(-80)	(-80)	(-80)
				(-80)	(-80)	(-80)	(-80)	(-80)	(-80)	(-80)	(-80)	(-80)	(-80)	(-80)	(-80)	(-80)	(-80)	(-80)	(-80)	(-80)	(-80)	(-80)	(-80)	(-80)	(-80)	(-80)	(-80)	(-80)	(-80)	(-80)	(-80)	(-80)	(-80)	(-80)	(-80)
				(-80)	(-80)	(-80)	(-80)	(-80)	(-80)	(-80)	(-80)	(-80)	(-80)	(-80)	(-80)	(-80)	(-80)	(-80)	(-80)	(-80)	(-80)	(-80)	(-80)	(-80)	(-80)	(-80)	(-80)	(-80)	(-80)	(-80)	(-80)	(-80)	(-80)	(-80)	(-80)
				(-80)	(-80)	(-80)	(-80)	(-80)	(-80)	(-80)	(-80)	(-80)	(-80)	(-80)	(-80)	(-80)	(-80)	(-80)	(-80)	(-80)	(-80)	(-80)	(-80)	(-80)	(-80)	(-80)	(-80)	(-80)	(-80)	(-80)	(-80)	(-80)	(-80)	(-80)	(-80)
				(-80)	(-80)	(-80)	(-80)	(-80)	(-80)	(-80)	(-80)	(-80)	(-80)	(-80)	(-80)	(-80)	(-80)	(-80)	(-80)	(-80)	(-80)	(-80)	(-80)	(-80)	(-80)	(-80)	(-80)	(-80)	(-80)	(-80)	(-80)	(-80)	(-80)	(-80)	(-80)
				(-80)	(-80)	(-80)	(-80)	(-80)	(-80)	(-80)	(-80)	(-80)	(-80)	(-80)	(-80)	(-80)	(-80)	(-80)	(-80)	(-80)	(-80)	(-80)	(-80)	(-80)	(-80)	(-80)	(-80)	(-80)	(-80)	(-80)	(-80)	(-80)	(-80)	(-80)	(-80)
				(-80)	(-80)	(-80)	(-80)	(-80)	(-80)	(-80)	(-80)	(-80)	(-80)	(-80)	(-80)	(-80)	(-80)	(-80)	(-80)	(-80)	(-80)	(-80)	(-80)	(-80)	(-80)	(-80)	(-80)	(-80)	(-80)	(-80)	(-80)	(-80)	(-80)	(-80)	(-80)
				(-80)	(-80)	(-80)	(-80)	(-80)	(-80)	(-80)	(-80)	(-80)	(-80)	(-80)	(-80)	(-80)	(-80)	(-80)	(-80)	(-80)	(-80)	(-80)	(-80)	(-80)	(-80)	(-80)	(-80)	(-80)	(-80)	(-80)	(-80)	(-80)	(-80)	(-80)	(-80)
				(-80)	(-80)	(-80)	(-80)	(-80)	(-80)	(-80)	(-80)	(-80)	(-80)	(-80)	(-80)	(-80)	(-80)	(-80)	(-80)	(-80)	(-80)	(-80)	(-80)	(-80)	(-80)	(-80)	(-80)	(-80)	(-80)	(-80)	(-80)	(-80)	(-80)	(-80)	(-80)
				(-80)	(-80)	(-80)	(-80)	(-80)	(-80)	(-80)	(-80)	(-80)	(-80)	(-80)	(-80)	(-80)	(-80)	(-80)	(-80)	(-80)	(-80)	(-80)	(-80)	(-80)	(-80)	(-80)	(-80)	(-80)	(-80)	(-80)	(-80)	(-80)	(-80)	(-80)	(-80)
				(-80)	(-80)	(-80)	(-80)	(-80)	(-80)	(-80)	(-80)	(-80)	(-80)	(-80)	(-80)	(-80)	(-80)	(-80)	(-80)	(-80)	(-80)	(-80)	(-80)	(-80)	(-80)	(-80)	(-80)	(-80)	(-80)	(-80)	(-80)	(-80)	(-80)	(-80)	(-80)
				(-80)	(-80)	(-80)	(-80)	(-80)	(-80)	(-80)	(-80)	(-80)	(-80)	(-80)	(-80)	(-80)	(-80)	(-80)	(-80)	(-80)	(-80)	(-80)	(-80)	(-80)	(-80)	(-80)	(-80)	(-80)	(-80)	(-80)	(-80)	(-80)	(-80)	(-80)	(-80)
				(-80)	(-80)	(-80)	(-80)	(-80)	(-80)	(-80)	(-80)	(-80)	(-80)	(-80)	(-80)	(-80)	(-80)	(-80)	(-80)	(-80)	(-80)	(-80)	(-80)	(-80)	(-80)	(-80)	(-80)	(-80)	(-80)	(-80)	(-80)	(-80)	(-80)	(-80)	(-80)
				(-80)	(-80)	(-80)	(-80)	(-80)	(-80)	(-80)	(-80)	(-80)	(-80)	(-80)	(-80)	(-80)	(-80)	(-80)	(-80)	(-80)	(-80)	(-80)	(-80)	(-80)	(-80)	(-80)	(-80)	(-80)	(-80)	(-80)	(-80)	(-80)	(-80)	(-80)	(-80)
				(-75) (-75) (-75)>;

			PS_Config_Diff_Test_Frame = <50>;
		};
	};
};
